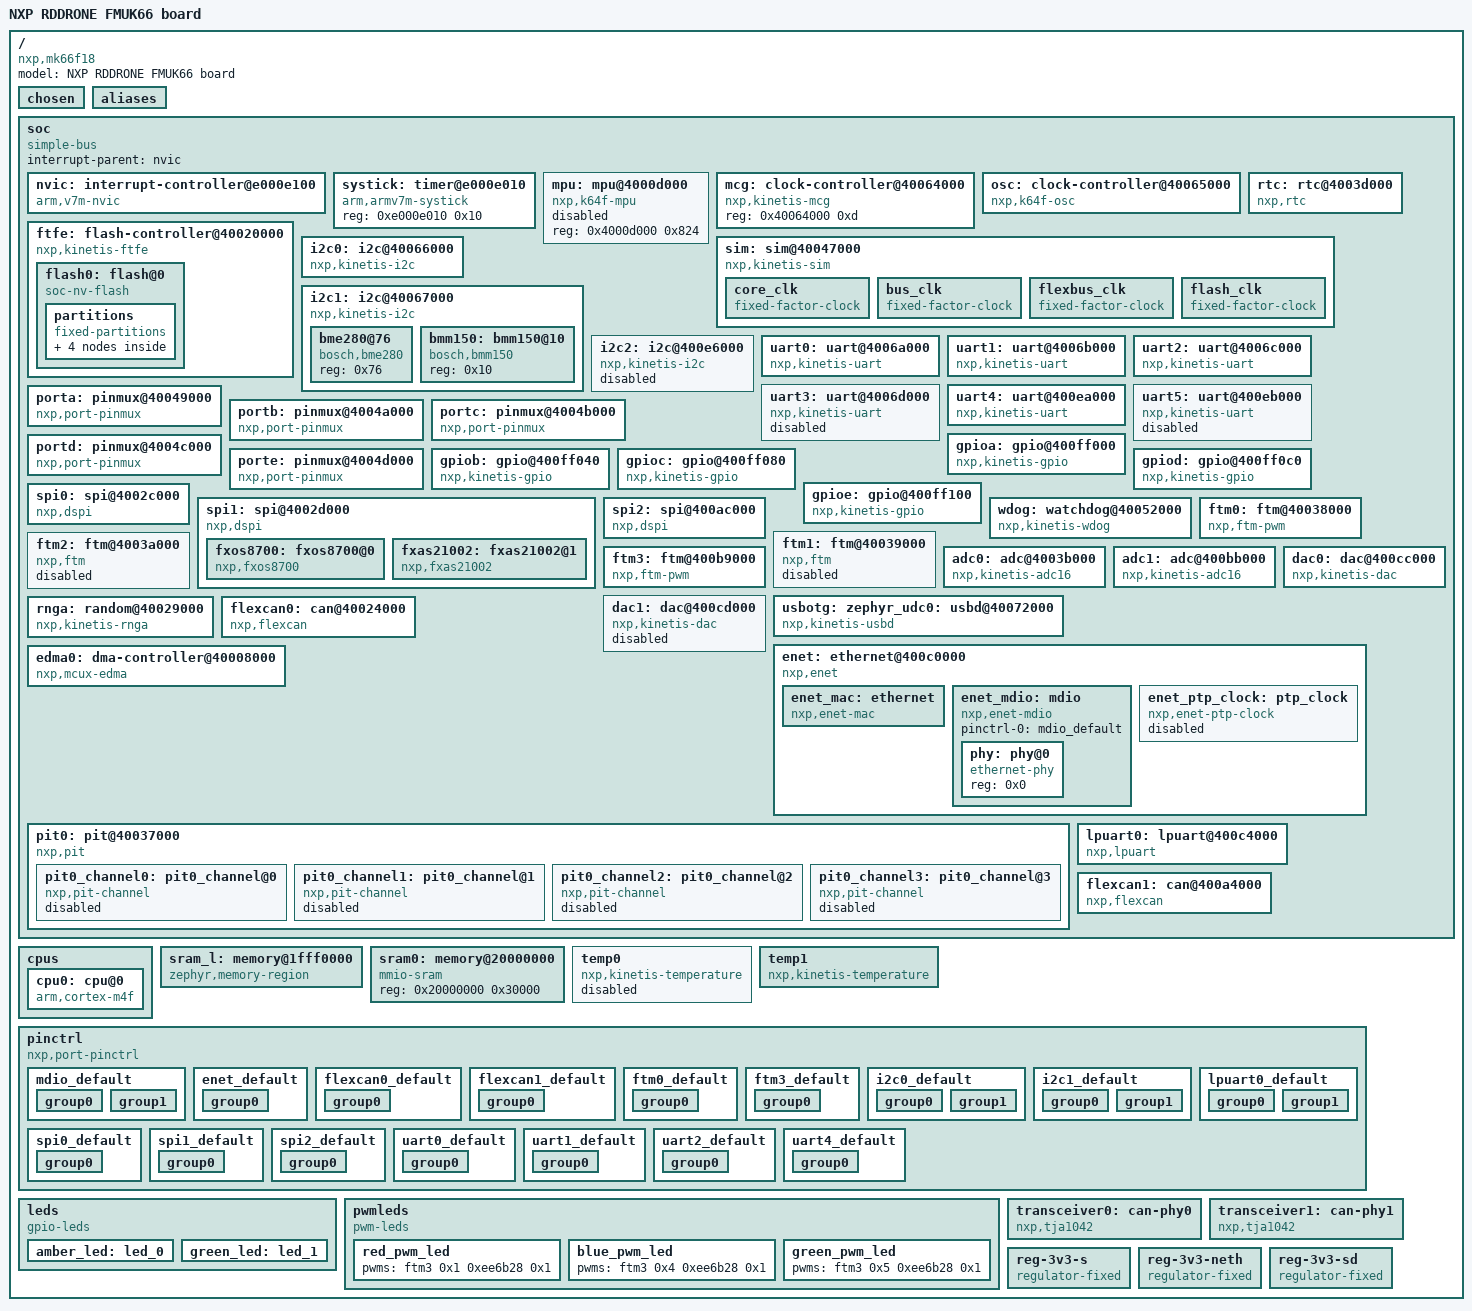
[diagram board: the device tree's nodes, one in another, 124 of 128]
/dts-v1/;

/* node '/' defined in zephyr/dts/common/skeleton.dtsi:9 */
/ {
	#address-cells = < 0x1 >;           /* in zephyr/dts/common/skeleton.dtsi:10 */
	#size-cells = < 0x1 >;              /* in zephyr/dts/common/skeleton.dtsi:11 */
	model = "NXP RDDRONE FMUK66 board"; /* in zephyr/boards/nxp/rddrone_fmuk66/rddrone_fmuk66.dts:15 */
	compatible = "nxp,mk66f18",
	             "nxp,k66f",
	             "nxp,k6x";             /* in zephyr/boards/nxp/rddrone_fmuk66/rddrone_fmuk66.dts:16 */

	/* node '/chosen' defined in zephyr/dts/common/skeleton.dtsi:13 */
	chosen {
		zephyr,entropy = &rnga;                   /* in zephyr/dts/arm/nxp/nxp_k6x.dtsi:18 */
		zephyr,flash-controller = &ftfe;          /* in zephyr/dts/arm/nxp/nxp_k6x.dtsi:19 */
		zephyr,sram = &sram0;                     /* in zephyr/boards/nxp/rddrone_fmuk66/rddrone_fmuk66.dts:38 */
		zephyr,flash = &flash0;                   /* in zephyr/boards/nxp/rddrone_fmuk66/rddrone_fmuk66.dts:39 */
		zephyr,code-partition = &slot0_partition; /* in zephyr/boards/nxp/rddrone_fmuk66/rddrone_fmuk66.dts:40 */
		zephyr,uart-mcumgr = &lpuart0;            /* in zephyr/boards/nxp/rddrone_fmuk66/rddrone_fmuk66.dts:41 */
		zephyr,console = &lpuart0;                /* in zephyr/boards/nxp/rddrone_fmuk66/rddrone_fmuk66.dts:42 */
		zephyr,shell-uart = &lpuart0;             /* in zephyr/boards/nxp/rddrone_fmuk66/rddrone_fmuk66.dts:43 */
		zephyr,uart-pipe = &lpuart0;              /* in zephyr/boards/nxp/rddrone_fmuk66/rddrone_fmuk66.dts:44 */
		zephyr,canbus = &flexcan0;                /* in zephyr/boards/nxp/rddrone_fmuk66/rddrone_fmuk66.dts:45 */
	};

	/* node '/aliases' defined in zephyr/dts/common/skeleton.dtsi:15 */
	aliases {
		watchdog0 = &wdog;              /* in zephyr/dts/arm/nxp/nxp_k6x.dtsi:14 */
		led0 = &amber_led;              /* in zephyr/boards/nxp/rddrone_fmuk66/rddrone_fmuk66.dts:19 */
		led1 = &green_led;              /* in zephyr/boards/nxp/rddrone_fmuk66/rddrone_fmuk66.dts:20 */
		pwm-led0 = &red_pwm_led;        /* in zephyr/boards/nxp/rddrone_fmuk66/rddrone_fmuk66.dts:21 */
		pwm-led1 = &green_pwm_led;      /* in zephyr/boards/nxp/rddrone_fmuk66/rddrone_fmuk66.dts:22 */
		pwm-led2 = &blue_pwm_led;       /* in zephyr/boards/nxp/rddrone_fmuk66/rddrone_fmuk66.dts:23 */
		magn0 = &bmm150;                /* in zephyr/boards/nxp/rddrone_fmuk66/rddrone_fmuk66.dts:24 */
		red-pwm-led = &red_pwm_led;     /* in zephyr/boards/nxp/rddrone_fmuk66/rddrone_fmuk66.dts:25 */
		green-pwm-led = &green_pwm_led; /* in zephyr/boards/nxp/rddrone_fmuk66/rddrone_fmuk66.dts:26 */
		blue-pwm-led = &blue_pwm_led;   /* in zephyr/boards/nxp/rddrone_fmuk66/rddrone_fmuk66.dts:27 */
		accel0 = &fxos8700;             /* in zephyr/boards/nxp/rddrone_fmuk66/rddrone_fmuk66.dts:28 */
	};

	/* node '/soc' defined in zephyr/dts/arm/armv7-m.dtsi:6 */
	soc {
		#address-cells = < 0x1 >;     /* in zephyr/dts/arm/armv7-m.dtsi:7 */
		#size-cells = < 0x1 >;        /* in zephyr/dts/arm/armv7-m.dtsi:8 */
		compatible = "simple-bus";    /* in zephyr/dts/arm/armv7-m.dtsi:9 */
		interrupt-parent = < &nvic >; /* in zephyr/dts/arm/armv7-m.dtsi:10 */
		ranges;                       /* in zephyr/dts/arm/armv7-m.dtsi:11 */

		/* node '/soc/interrupt-controller@e000e100' defined in zephyr/dts/arm/armv7-m.dtsi:13 */
		nvic: interrupt-controller@e000e100 {
			#address-cells = < 0x1 >;            /* in zephyr/dts/arm/armv7-m.dtsi:14 */
			compatible = "arm,v7m-nvic";         /* in zephyr/dts/arm/armv7-m.dtsi:15 */
			reg = < 0xe000e100 0xc00 >;          /* in zephyr/dts/arm/armv7-m.dtsi:16 */
			interrupt-controller;                /* in zephyr/dts/arm/armv7-m.dtsi:17 */
			#interrupt-cells = < 0x2 >;          /* in zephyr/dts/arm/armv7-m.dtsi:18 */
			arm,num-irq-priority-bits = < 0x4 >; /* in zephyr/dts/arm/nxp/nxp_k6x.dtsi:584 */
			phandle = < 0x1 >;                   /* in zephyr/dts/arm/armv7-m.dtsi:10 */
		};

		/* node '/soc/timer@e000e010' defined in zephyr/dts/arm/armv7-m.dtsi:21 */
		systick: timer@e000e010 {
			compatible = "arm,armv7m-systick"; /* in zephyr/dts/arm/armv7-m.dtsi:22 */
			reg = < 0xe000e010 0x10 >;         /* in zephyr/dts/arm/armv7-m.dtsi:23 */
		};

		/* node '/soc/mpu@4000d000' defined in zephyr/dts/arm/nxp/nxp_k6x.dtsi:82 */
		mpu: mpu@4000d000 {
			compatible = "nxp,k64f-mpu"; /* in zephyr/dts/arm/nxp/nxp_k6x.dtsi:83 */
			reg = < 0x4000d000 0x824 >;  /* in zephyr/dts/arm/nxp/nxp_k6x.dtsi:84 */
			status = "disabled";         /* in zephyr/dts/arm/nxp/nxp_k6x.dtsi:86 */
		};

		/* node '/soc/clock-controller@40064000' defined in zephyr/dts/arm/nxp/nxp_k6x.dtsi:89 */
		mcg: clock-controller@40064000 {
			compatible = "nxp,kinetis-mcg"; /* in zephyr/dts/arm/nxp/nxp_k6x.dtsi:90 */
			reg = < 0x40064000 0xd >;       /* in zephyr/dts/arm/nxp/nxp_k6x.dtsi:91 */
			#clock-cells = < 0x1 >;         /* in zephyr/dts/arm/nxp/nxp_k6x.dtsi:92 */
			phandle = < 0x2 >;              /* in zephyr/dts/arm/nxp/nxp_k6x.dtsi:118 */
		};

		/* node '/soc/clock-controller@40065000' defined in zephyr/dts/arm/nxp/nxp_k6x.dtsi:95 */
		osc: clock-controller@40065000 {
			compatible = "nxp,k64f-osc"; /* in zephyr/dts/arm/nxp/nxp_k6x.dtsi:96 */
			reg = < 0x40065000 0x4 >;    /* in zephyr/dts/arm/nxp/nxp_k6x.dtsi:97 */
			enable-external-reference;   /* in zephyr/dts/arm/nxp/nxp_k6x.dtsi:99 */
		};

		/* node '/soc/rtc@4003d000' defined in zephyr/dts/arm/nxp/nxp_k6x.dtsi:102 */
		rtc: rtc@4003d000 {
			compatible = "nxp,rtc";       /* in zephyr/dts/arm/nxp/nxp_k6x.dtsi:103 */
			reg = < 0x4003d000 0x1000 >;  /* in zephyr/dts/arm/nxp/nxp_k6x.dtsi:104 */
			interrupts = < 0x2e 0x0 >,
			             < 0x2f 0x0 >;    /* in zephyr/dts/arm/nxp/nxp_k6x.dtsi:105 */
			interrupt-names = "alarm",
			                  "seconds";  /* in zephyr/dts/arm/nxp/nxp_k6x.dtsi:106 */
			clock-frequency = < 0x8000 >; /* in zephyr/dts/arm/nxp/nxp_k6x.dtsi:107 */
			prescaler = < 0x8000 >;       /* in zephyr/dts/arm/nxp/nxp_k6x.dtsi:108 */
		};

		/* node '/soc/sim@40047000' defined in zephyr/dts/arm/nxp/nxp_k6x.dtsi:111 */
		sim: sim@40047000 {
			compatible = "nxp,kinetis-sim"; /* in zephyr/dts/arm/nxp/nxp_k6x.dtsi:112 */
			reg = < 0x40047000 0x1060 >;    /* in zephyr/dts/arm/nxp/nxp_k6x.dtsi:113 */
			#clock-cells = < 0x3 >;         /* in zephyr/dts/arm/nxp/nxp_k6x.dtsi:114 */
			pllfll-select = < 0x1 >;        /* in zephyr/boards/nxp/rddrone_fmuk66/rddrone_fmuk66.dts:122 */
			er32k-select = < 0x2 >;         /* in zephyr/boards/nxp/rddrone_fmuk66/rddrone_fmuk66.dts:123 */
			phandle = < 0x3 >;              /* in zephyr/dts/arm/nxp/nxp_k6x.dtsi:170 */

			/* node '/soc/sim@40047000/core_clk' defined in zephyr/dts/arm/nxp/nxp_k6x.dtsi:116 */
			core_clk {
				compatible = "fixed-factor-clock"; /* in zephyr/dts/arm/nxp/nxp_k6x.dtsi:117 */
				clocks = < &mcg 0x1 >;             /* in zephyr/dts/arm/nxp/nxp_k6x.dtsi:118 */
				clock-div = < 0x1 >;               /* in zephyr/dts/arm/nxp/nxp_k6x.dtsi:119 */
				#clock-cells = < 0x0 >;            /* in zephyr/dts/arm/nxp/nxp_k6x.dtsi:120 */
			};

			/* node '/soc/sim@40047000/bus_clk' defined in zephyr/dts/arm/nxp/nxp_k6x.dtsi:123 */
			bus_clk {
				compatible = "fixed-factor-clock"; /* in zephyr/dts/arm/nxp/nxp_k6x.dtsi:124 */
				clocks = < &mcg 0x1 >;             /* in zephyr/dts/arm/nxp/nxp_k6x.dtsi:125 */
				clock-div = < 0x2 >;               /* in zephyr/dts/arm/nxp/nxp_k6x.dtsi:126 */
				#clock-cells = < 0x0 >;            /* in zephyr/dts/arm/nxp/nxp_k6x.dtsi:127 */
			};

			/* node '/soc/sim@40047000/flexbus_clk' defined in zephyr/dts/arm/nxp/nxp_k6x.dtsi:130 */
			flexbus_clk {
				compatible = "fixed-factor-clock"; /* in zephyr/dts/arm/nxp/nxp_k6x.dtsi:131 */
				clocks = < &mcg 0x1 >;             /* in zephyr/dts/arm/nxp/nxp_k6x.dtsi:132 */
				clock-div = < 0x3 >;               /* in zephyr/dts/arm/nxp/nxp_k6x.dtsi:133 */
				#clock-cells = < 0x0 >;            /* in zephyr/dts/arm/nxp/nxp_k6x.dtsi:134 */
			};

			/* node '/soc/sim@40047000/flash_clk' defined in zephyr/dts/arm/nxp/nxp_k6x.dtsi:137 */
			flash_clk {
				compatible = "fixed-factor-clock"; /* in zephyr/dts/arm/nxp/nxp_k6x.dtsi:138 */
				clocks = < &mcg 0x1 >;             /* in zephyr/dts/arm/nxp/nxp_k6x.dtsi:139 */
				clock-div = < 0x5 >;               /* in zephyr/dts/arm/nxp/nxp_k6x.dtsi:140 */
				#clock-cells = < 0x0 >;            /* in zephyr/dts/arm/nxp/nxp_k6x.dtsi:141 */
			};
		};

		/* node '/soc/flash-controller@40020000' defined in zephyr/dts/arm/nxp/nxp_k6x.dtsi:145 */
		ftfe: flash-controller@40020000 {
			compatible = "nxp,kinetis-ftfe";      /* in zephyr/dts/arm/nxp/nxp_k6x.dtsi:146 */
			reg = < 0x40020000 0x18 >;            /* in zephyr/dts/arm/nxp/nxp_k6x.dtsi:147 */
			interrupts = < 0x12 0x0 >,
			             < 0x13 0x0 >;            /* in zephyr/dts/arm/nxp/nxp_k6x.dtsi:148 */
			interrupt-names = "command-complete",
			                  "read-collision";   /* in zephyr/dts/arm/nxp/nxp_k6x.dtsi:149 */
			status = "okay";                      /* in zephyr/dts/arm/nxp/nxp_k6x.dtsi:150 */
			#address-cells = < 0x1 >;             /* in zephyr/dts/arm/nxp/nxp_k6x.dtsi:152 */
			#size-cells = < 0x1 >;                /* in zephyr/dts/arm/nxp/nxp_k6x.dtsi:153 */

			/* node '/soc/flash-controller@40020000/flash@0' defined in zephyr/dts/arm/nxp/nxp_k6x.dtsi:155 */
			flash0: flash@0 {
				compatible = "soc-nv-flash";   /* in zephyr/dts/arm/nxp/nxp_k6x.dtsi:156 */
				erase-block-size = < 0x1000 >; /* in zephyr/dts/arm/nxp/nxp_k6x.dtsi:158 */
				write-block-size = < 0x8 >;    /* in zephyr/dts/arm/nxp/nxp_k6x.dtsi:159 */
				reg = < 0x0 0x200000 >;        /* in zephyr/dts/arm/nxp/nxp_k66.dtsi:12 */

				/* node '/soc/flash-controller@40020000/flash@0/partitions' defined in zephyr/boards/nxp/rddrone_fmuk66/rddrone_fmuk66.dts:236 */
				partitions {
					compatible = "fixed-partitions"; /* in zephyr/boards/nxp/rddrone_fmuk66/rddrone_fmuk66.dts:237 */
					#address-cells = < 0x1 >;        /* in zephyr/boards/nxp/rddrone_fmuk66/rddrone_fmuk66.dts:238 */
					#size-cells = < 0x1 >;           /* in zephyr/boards/nxp/rddrone_fmuk66/rddrone_fmuk66.dts:239 */

					/* node '/soc/flash-controller@40020000/flash@0/partitions/partition@0' defined in zephyr/boards/nxp/rddrone_fmuk66/rddrone_fmuk66.dts:245 */
					boot_partition: partition@0 {
						label = "mcuboot";     /* in zephyr/boards/nxp/rddrone_fmuk66/rddrone_fmuk66.dts:246 */
						reg = < 0x0 0x10000 >; /* in zephyr/boards/nxp/rddrone_fmuk66/rddrone_fmuk66.dts:247 */
						read-only;             /* in zephyr/boards/nxp/rddrone_fmuk66/rddrone_fmuk66.dts:248 */
					};

					/* node '/soc/flash-controller@40020000/flash@0/partitions/partition@10000' defined in zephyr/boards/nxp/rddrone_fmuk66/rddrone_fmuk66.dts:251 */
					slot0_partition: partition@10000 {
						label = "image-0";         /* in zephyr/boards/nxp/rddrone_fmuk66/rddrone_fmuk66.dts:252 */
						reg = < 0x10000 0xe9000 >; /* in zephyr/boards/nxp/rddrone_fmuk66/rddrone_fmuk66.dts:253 */
					};

					/* node '/soc/flash-controller@40020000/flash@0/partitions/partition@F9000' defined in zephyr/boards/nxp/rddrone_fmuk66/rddrone_fmuk66.dts:256 */
					slot1_partition: partition@F9000 {
						label = "image-1";         /* in zephyr/boards/nxp/rddrone_fmuk66/rddrone_fmuk66.dts:257 */
						reg = < 0xf9000 0xe9000 >; /* in zephyr/boards/nxp/rddrone_fmuk66/rddrone_fmuk66.dts:258 */
					};

					/* node '/soc/flash-controller@40020000/flash@0/partitions/partition@1E2000' defined in zephyr/boards/nxp/rddrone_fmuk66/rddrone_fmuk66.dts:261 */
					storage_partition: partition@1E2000 {
						label = "storage";          /* in zephyr/boards/nxp/rddrone_fmuk66/rddrone_fmuk66.dts:262 */
						reg = < 0x1e2000 0x1e000 >; /* in zephyr/boards/nxp/rddrone_fmuk66/rddrone_fmuk66.dts:263 */
					};
				};
			};
		};

		/* node '/soc/i2c@40066000' defined in zephyr/dts/arm/nxp/nxp_k6x.dtsi:163 */
		i2c0: i2c@40066000 {
			compatible = "nxp,kinetis-i2c";   /* in zephyr/dts/arm/nxp/nxp_k6x.dtsi:164 */
			clock-frequency = < 0x186a0 >;    /* in zephyr/dts/arm/nxp/nxp_k6x.dtsi:165 */
			#address-cells = < 0x1 >;         /* in zephyr/dts/arm/nxp/nxp_k6x.dtsi:166 */
			#size-cells = < 0x0 >;            /* in zephyr/dts/arm/nxp/nxp_k6x.dtsi:167 */
			reg = < 0x40066000 0x1000 >;      /* in zephyr/dts/arm/nxp/nxp_k6x.dtsi:168 */
			interrupts = < 0x18 0x0 >;        /* in zephyr/dts/arm/nxp/nxp_k6x.dtsi:169 */
			clocks = < &sim 0x2 0x1034 0x6 >; /* in zephyr/dts/arm/nxp/nxp_k6x.dtsi:170 */
			status = "okay";                  /* in zephyr/boards/nxp/rddrone_fmuk66/rddrone_fmuk66.dts:305 */
			pinctrl-0 = < &i2c0_default >;    /* in zephyr/boards/nxp/rddrone_fmuk66/rddrone_fmuk66.dts:306 */
			pinctrl-names = "default";        /* in zephyr/boards/nxp/rddrone_fmuk66/rddrone_fmuk66.dts:307 */
		};

		/* node '/soc/i2c@40067000' defined in zephyr/dts/arm/nxp/nxp_k6x.dtsi:174 */
		i2c1: i2c@40067000 {
			compatible = "nxp,kinetis-i2c";   /* in zephyr/dts/arm/nxp/nxp_k6x.dtsi:175 */
			clock-frequency = < 0x186a0 >;    /* in zephyr/dts/arm/nxp/nxp_k6x.dtsi:176 */
			#address-cells = < 0x1 >;         /* in zephyr/dts/arm/nxp/nxp_k6x.dtsi:177 */
			#size-cells = < 0x0 >;            /* in zephyr/dts/arm/nxp/nxp_k6x.dtsi:178 */
			reg = < 0x40067000 0x1000 >;      /* in zephyr/dts/arm/nxp/nxp_k6x.dtsi:179 */
			interrupts = < 0x19 0x0 >;        /* in zephyr/dts/arm/nxp/nxp_k6x.dtsi:180 */
			clocks = < &sim 0x2 0x1034 0x7 >; /* in zephyr/dts/arm/nxp/nxp_k6x.dtsi:181 */
			status = "okay";                  /* in zephyr/boards/nxp/rddrone_fmuk66/rddrone_fmuk66.dts:314 */
			pinctrl-0 = < &i2c1_default >;    /* in zephyr/boards/nxp/rddrone_fmuk66/rddrone_fmuk66.dts:315 */
			pinctrl-names = "default";        /* in zephyr/boards/nxp/rddrone_fmuk66/rddrone_fmuk66.dts:316 */

			/* node '/soc/i2c@40067000/bme280@76' defined in zephyr/boards/nxp/rddrone_fmuk66/rddrone_fmuk66.dts:323 */
			bme280@76 {
				compatible = "bosch,bme280"; /* in zephyr/boards/nxp/rddrone_fmuk66/rddrone_fmuk66.dts:324 */
				status = "okay";             /* in zephyr/boards/nxp/rddrone_fmuk66/rddrone_fmuk66.dts:325 */
				reg = < 0x76 >;              /* in zephyr/boards/nxp/rddrone_fmuk66/rddrone_fmuk66.dts:326 */
			};

			/* node '/soc/i2c@40067000/bmm150@10' defined in zephyr/boards/nxp/rddrone_fmuk66/rddrone_fmuk66.dts:329 */
			bmm150: bmm150@10 {
				compatible = "bosch,bmm150"; /* in zephyr/boards/nxp/rddrone_fmuk66/rddrone_fmuk66.dts:330 */
				status = "okay";             /* in zephyr/boards/nxp/rddrone_fmuk66/rddrone_fmuk66.dts:331 */
				reg = < 0x10 >;              /* in zephyr/boards/nxp/rddrone_fmuk66/rddrone_fmuk66.dts:332 */
			};
		};

		/* node '/soc/i2c@400e6000' defined in zephyr/dts/arm/nxp/nxp_k6x.dtsi:185 */
		i2c2: i2c@400e6000 {
			compatible = "nxp,kinetis-i2c";   /* in zephyr/dts/arm/nxp/nxp_k6x.dtsi:186 */
			clock-frequency = < 0x186a0 >;    /* in zephyr/dts/arm/nxp/nxp_k6x.dtsi:187 */
			#address-cells = < 0x1 >;         /* in zephyr/dts/arm/nxp/nxp_k6x.dtsi:188 */
			#size-cells = < 0x0 >;            /* in zephyr/dts/arm/nxp/nxp_k6x.dtsi:189 */
			reg = < 0x400e6000 0x1000 >;      /* in zephyr/dts/arm/nxp/nxp_k6x.dtsi:190 */
			interrupts = < 0x4a 0x0 >;        /* in zephyr/dts/arm/nxp/nxp_k6x.dtsi:191 */
			clocks = < &sim 0x2 0x1028 0x6 >; /* in zephyr/dts/arm/nxp/nxp_k6x.dtsi:192 */
			status = "disabled";              /* in zephyr/dts/arm/nxp/nxp_k6x.dtsi:193 */
		};

		/* node '/soc/uart@4006a000' defined in zephyr/dts/arm/nxp/nxp_k6x.dtsi:196 */
		uart0: uart@4006a000 {
			compatible = "nxp,kinetis-uart";  /* in zephyr/dts/arm/nxp/nxp_k6x.dtsi:197 */
			reg = < 0x4006a000 0x1000 >;      /* in zephyr/dts/arm/nxp/nxp_k6x.dtsi:198 */
			interrupts = < 0x1f 0x0 >,
			             < 0x20 0x0 >;        /* in zephyr/dts/arm/nxp/nxp_k6x.dtsi:199 */
			interrupt-names = "status",
			                  "error";        /* in zephyr/dts/arm/nxp/nxp_k6x.dtsi:200 */
			clocks = < &sim 0x0 0x1034 0xa >; /* in zephyr/dts/arm/nxp/nxp_k6x.dtsi:201 */
			status = "okay";                  /* in zephyr/boards/nxp/rddrone_fmuk66/rddrone_fmuk66.dts:182 */
			current-speed = < 0x1c200 >;      /* in zephyr/boards/nxp/rddrone_fmuk66/rddrone_fmuk66.dts:183 */
			pinctrl-0 = < &uart0_default >;   /* in zephyr/boards/nxp/rddrone_fmuk66/rddrone_fmuk66.dts:184 */
			pinctrl-names = "default";        /* in zephyr/boards/nxp/rddrone_fmuk66/rddrone_fmuk66.dts:185 */
		};

		/* node '/soc/uart@4006b000' defined in zephyr/dts/arm/nxp/nxp_k6x.dtsi:206 */
		uart1: uart@4006b000 {
			compatible = "nxp,kinetis-uart";  /* in zephyr/dts/arm/nxp/nxp_k6x.dtsi:207 */
			reg = < 0x4006b000 0x1000 >;      /* in zephyr/dts/arm/nxp/nxp_k6x.dtsi:208 */
			interrupts = < 0x21 0x0 >,
			             < 0x22 0x0 >;        /* in zephyr/dts/arm/nxp/nxp_k6x.dtsi:209 */
			interrupt-names = "status",
			                  "error";        /* in zephyr/dts/arm/nxp/nxp_k6x.dtsi:210 */
			clocks = < &sim 0x0 0x1034 0xb >; /* in zephyr/dts/arm/nxp/nxp_k6x.dtsi:211 */
			status = "okay";                  /* in zephyr/boards/nxp/rddrone_fmuk66/rddrone_fmuk66.dts:189 */
			current-speed = < 0x1c200 >;      /* in zephyr/boards/nxp/rddrone_fmuk66/rddrone_fmuk66.dts:190 */
			pinctrl-0 = < &uart1_default >;   /* in zephyr/boards/nxp/rddrone_fmuk66/rddrone_fmuk66.dts:191 */
			pinctrl-names = "default";        /* in zephyr/boards/nxp/rddrone_fmuk66/rddrone_fmuk66.dts:192 */
		};

		/* node '/soc/uart@4006c000' defined in zephyr/dts/arm/nxp/nxp_k6x.dtsi:216 */
		uart2: uart@4006c000 {
			compatible = "nxp,kinetis-uart";  /* in zephyr/dts/arm/nxp/nxp_k6x.dtsi:217 */
			reg = < 0x4006c000 0x1000 >;      /* in zephyr/dts/arm/nxp/nxp_k6x.dtsi:218 */
			interrupts = < 0x23 0x0 >,
			             < 0x24 0x0 >;        /* in zephyr/dts/arm/nxp/nxp_k6x.dtsi:219 */
			interrupt-names = "status",
			                  "error";        /* in zephyr/dts/arm/nxp/nxp_k6x.dtsi:220 */
			clocks = < &sim 0x2 0x1034 0xc >; /* in zephyr/dts/arm/nxp/nxp_k6x.dtsi:221 */
			status = "okay";                  /* in zephyr/boards/nxp/rddrone_fmuk66/rddrone_fmuk66.dts:196 */
			current-speed = < 0x1c200 >;      /* in zephyr/boards/nxp/rddrone_fmuk66/rddrone_fmuk66.dts:197 */
			pinctrl-0 = < &uart2_default >;   /* in zephyr/boards/nxp/rddrone_fmuk66/rddrone_fmuk66.dts:198 */
			pinctrl-names = "default";        /* in zephyr/boards/nxp/rddrone_fmuk66/rddrone_fmuk66.dts:199 */
		};

		/* node '/soc/uart@4006d000' defined in zephyr/dts/arm/nxp/nxp_k6x.dtsi:226 */
		uart3: uart@4006d000 {
			compatible = "nxp,kinetis-uart";  /* in zephyr/dts/arm/nxp/nxp_k6x.dtsi:227 */
			reg = < 0x4006d000 0x1000 >;      /* in zephyr/dts/arm/nxp/nxp_k6x.dtsi:228 */
			interrupts = < 0x25 0x0 >,
			             < 0x26 0x0 >;        /* in zephyr/dts/arm/nxp/nxp_k6x.dtsi:229 */
			interrupt-names = "status",
			                  "error";        /* in zephyr/dts/arm/nxp/nxp_k6x.dtsi:230 */
			clocks = < &sim 0x2 0x1034 0xd >; /* in zephyr/dts/arm/nxp/nxp_k6x.dtsi:231 */
			status = "disabled";              /* in zephyr/dts/arm/nxp/nxp_k6x.dtsi:233 */
		};

		/* node '/soc/uart@400ea000' defined in zephyr/dts/arm/nxp/nxp_k6x.dtsi:236 */
		uart4: uart@400ea000 {
			compatible = "nxp,kinetis-uart";  /* in zephyr/dts/arm/nxp/nxp_k6x.dtsi:237 */
			reg = < 0x400ea000 0x1000 >;      /* in zephyr/dts/arm/nxp/nxp_k6x.dtsi:238 */
			interrupts = < 0x42 0x0 >,
			             < 0x43 0x0 >;        /* in zephyr/dts/arm/nxp/nxp_k6x.dtsi:239 */
			interrupt-names = "status",
			                  "error";        /* in zephyr/dts/arm/nxp/nxp_k6x.dtsi:240 */
			clocks = < &sim 0x2 0x1028 0xa >; /* in zephyr/dts/arm/nxp/nxp_k6x.dtsi:241 */
			status = "okay";                  /* in zephyr/boards/nxp/rddrone_fmuk66/rddrone_fmuk66.dts:203 */
			current-speed = < 0x1c200 >;      /* in zephyr/boards/nxp/rddrone_fmuk66/rddrone_fmuk66.dts:204 */
			pinctrl-0 = < &uart4_default >;   /* in zephyr/boards/nxp/rddrone_fmuk66/rddrone_fmuk66.dts:205 */
			pinctrl-names = "default";        /* in zephyr/boards/nxp/rddrone_fmuk66/rddrone_fmuk66.dts:206 */
		};

		/* node '/soc/uart@400eb000' defined in zephyr/dts/arm/nxp/nxp_k6x.dtsi:246 */
		uart5: uart@400eb000 {
			compatible = "nxp,kinetis-uart";  /* in zephyr/dts/arm/nxp/nxp_k6x.dtsi:247 */
			reg = < 0x400eb000 0x1000 >;      /* in zephyr/dts/arm/nxp/nxp_k6x.dtsi:248 */
			interrupts = < 0x44 0x0 >,
			             < 0x45 0x0 >;        /* in zephyr/dts/arm/nxp/nxp_k6x.dtsi:249 */
			interrupt-names = "status",
			                  "error";        /* in zephyr/dts/arm/nxp/nxp_k6x.dtsi:250 */
			clocks = < &sim 0x2 0x1028 0xb >; /* in zephyr/dts/arm/nxp/nxp_k6x.dtsi:251 */
			status = "disabled";              /* in zephyr/dts/arm/nxp/nxp_k6x.dtsi:253 */
		};

		/* node '/soc/pinmux@40049000' defined in zephyr/dts/arm/nxp/nxp_k6x.dtsi:256 */
		porta: pinmux@40049000 {
			compatible = "nxp,port-pinmux";   /* in zephyr/dts/arm/nxp/nxp_k6x.dtsi:257 */
			reg = < 0x40049000 0xd0 >;        /* in zephyr/dts/arm/nxp/nxp_k6x.dtsi:258 */
			clocks = < &sim 0x2 0x1038 0x9 >; /* in zephyr/dts/arm/nxp/nxp_k6x.dtsi:259 */
			phandle = < 0xa >;                /* in zephyr/dts/arm/nxp/nxp_k6x.dtsi:293 */
		};

		/* node '/soc/pinmux@4004a000' defined in zephyr/dts/arm/nxp/nxp_k6x.dtsi:262 */
		portb: pinmux@4004a000 {
			compatible = "nxp,port-pinmux";   /* in zephyr/dts/arm/nxp/nxp_k6x.dtsi:263 */
			reg = < 0x4004a000 0xd0 >;        /* in zephyr/dts/arm/nxp/nxp_k6x.dtsi:264 */
			clocks = < &sim 0x2 0x1038 0xa >; /* in zephyr/dts/arm/nxp/nxp_k6x.dtsi:265 */
			phandle = < 0xb >;                /* in zephyr/dts/arm/nxp/nxp_k6x.dtsi:303 */
		};

		/* node '/soc/pinmux@4004b000' defined in zephyr/dts/arm/nxp/nxp_k6x.dtsi:268 */
		portc: pinmux@4004b000 {
			compatible = "nxp,port-pinmux";   /* in zephyr/dts/arm/nxp/nxp_k6x.dtsi:269 */
			reg = < 0x4004b000 0xd0 >;        /* in zephyr/dts/arm/nxp/nxp_k6x.dtsi:270 */
			clocks = < &sim 0x2 0x1038 0xb >; /* in zephyr/dts/arm/nxp/nxp_k6x.dtsi:271 */
			phandle = < 0xc >;                /* in zephyr/dts/arm/nxp/nxp_k6x.dtsi:313 */
		};

		/* node '/soc/pinmux@4004c000' defined in zephyr/dts/arm/nxp/nxp_k6x.dtsi:274 */
		portd: pinmux@4004c000 {
			compatible = "nxp,port-pinmux";   /* in zephyr/dts/arm/nxp/nxp_k6x.dtsi:275 */
			reg = < 0x4004c000 0xd0 >;        /* in zephyr/dts/arm/nxp/nxp_k6x.dtsi:276 */
			clocks = < &sim 0x2 0x1038 0xc >; /* in zephyr/dts/arm/nxp/nxp_k6x.dtsi:277 */
			phandle = < 0xd >;                /* in zephyr/dts/arm/nxp/nxp_k6x.dtsi:323 */
		};

		/* node '/soc/pinmux@4004d000' defined in zephyr/dts/arm/nxp/nxp_k6x.dtsi:280 */
		porte: pinmux@4004d000 {
			compatible = "nxp,port-pinmux";   /* in zephyr/dts/arm/nxp/nxp_k6x.dtsi:281 */
			reg = < 0x4004d000 0xd0 >;        /* in zephyr/dts/arm/nxp/nxp_k6x.dtsi:282 */
			clocks = < &sim 0x2 0x1038 0xd >; /* in zephyr/dts/arm/nxp/nxp_k6x.dtsi:283 */
			phandle = < 0xe >;                /* in zephyr/dts/arm/nxp/nxp_k6x.dtsi:333 */
		};

		/* node '/soc/gpio@400ff000' defined in zephyr/dts/arm/nxp/nxp_k6x.dtsi:286 */
		gpioa: gpio@400ff000 {
			compatible = "nxp,kinetis-gpio"; /* in zephyr/dts/arm/nxp/nxp_k6x.dtsi:287 */
			reg = < 0x400ff000 0x40 >;       /* in zephyr/dts/arm/nxp/nxp_k6x.dtsi:289 */
			interrupts = < 0x3b 0x2 >;       /* in zephyr/dts/arm/nxp/nxp_k6x.dtsi:290 */
			gpio-controller;                 /* in zephyr/dts/arm/nxp/nxp_k6x.dtsi:291 */
			#gpio-cells = < 0x2 >;           /* in zephyr/dts/arm/nxp/nxp_k6x.dtsi:292 */
			nxp,kinetis-port = < &porta >;   /* in zephyr/dts/arm/nxp/nxp_k6x.dtsi:293 */
			status = "okay";                 /* in zephyr/boards/nxp/rddrone_fmuk66/rddrone_fmuk66.dts:216 */
			phandle = < 0x13 >;              /* in zephyr/boards/nxp/rddrone_fmuk66/rddrone_fmuk66.dts:361 */
		};

		/* node '/soc/gpio@400ff040' defined in zephyr/dts/arm/nxp/nxp_k6x.dtsi:296 */
		gpiob: gpio@400ff040 {
			compatible = "nxp,kinetis-gpio"; /* in zephyr/dts/arm/nxp/nxp_k6x.dtsi:297 */
			reg = < 0x400ff040 0x40 >;       /* in zephyr/dts/arm/nxp/nxp_k6x.dtsi:299 */
			interrupts = < 0x3c 0x2 >;       /* in zephyr/dts/arm/nxp/nxp_k6x.dtsi:300 */
			gpio-controller;                 /* in zephyr/dts/arm/nxp/nxp_k6x.dtsi:301 */
			#gpio-cells = < 0x2 >;           /* in zephyr/dts/arm/nxp/nxp_k6x.dtsi:302 */
			nxp,kinetis-port = < &portb >;   /* in zephyr/dts/arm/nxp/nxp_k6x.dtsi:303 */
			status = "okay";                 /* in zephyr/boards/nxp/rddrone_fmuk66/rddrone_fmuk66.dts:220 */
			phandle = < 0x12 >;              /* in zephyr/boards/nxp/rddrone_fmuk66/rddrone_fmuk66.dts:353 */
		};

		/* node '/soc/gpio@400ff080' defined in zephyr/dts/arm/nxp/nxp_k6x.dtsi:306 */
		gpioc: gpio@400ff080 {
			compatible = "nxp,kinetis-gpio"; /* in zephyr/dts/arm/nxp/nxp_k6x.dtsi:307 */
			reg = < 0x400ff080 0x40 >;       /* in zephyr/dts/arm/nxp/nxp_k6x.dtsi:309 */
			interrupts = < 0x3d 0x2 >;       /* in zephyr/dts/arm/nxp/nxp_k6x.dtsi:310 */
			gpio-controller;                 /* in zephyr/dts/arm/nxp/nxp_k6x.dtsi:311 */
			#gpio-cells = < 0x2 >;           /* in zephyr/dts/arm/nxp/nxp_k6x.dtsi:312 */
			nxp,kinetis-port = < &portc >;   /* in zephyr/dts/arm/nxp/nxp_k6x.dtsi:313 */
			status = "okay";                 /* in zephyr/boards/nxp/rddrone_fmuk66/rddrone_fmuk66.dts:224 */
			phandle = < 0x26 >;              /* in zephyr/boards/nxp/rddrone_fmuk66/rddrone_fmuk66.dts:81 */
		};

		/* node '/soc/gpio@400ff0c0' defined in zephyr/dts/arm/nxp/nxp_k6x.dtsi:316 */
		gpiod: gpio@400ff0c0 {
			compatible = "nxp,kinetis-gpio"; /* in zephyr/dts/arm/nxp/nxp_k6x.dtsi:317 */
			reg = < 0x400ff0c0 0x40 >;       /* in zephyr/dts/arm/nxp/nxp_k6x.dtsi:319 */
			interrupts = < 0x3e 0x2 >;       /* in zephyr/dts/arm/nxp/nxp_k6x.dtsi:320 */
			gpio-controller;                 /* in zephyr/dts/arm/nxp/nxp_k6x.dtsi:321 */
			#gpio-cells = < 0x2 >;           /* in zephyr/dts/arm/nxp/nxp_k6x.dtsi:322 */
			nxp,kinetis-port = < &portd >;   /* in zephyr/dts/arm/nxp/nxp_k6x.dtsi:323 */
			status = "okay";                 /* in zephyr/boards/nxp/rddrone_fmuk66/rddrone_fmuk66.dts:228 */
			phandle = < 0x15 >;              /* in zephyr/boards/nxp/rddrone_fmuk66/rddrone_fmuk66.dts:371 */
		};

		/* node '/soc/gpio@400ff100' defined in zephyr/dts/arm/nxp/nxp_k6x.dtsi:326 */
		gpioe: gpio@400ff100 {
			compatible = "nxp,kinetis-gpio"; /* in zephyr/dts/arm/nxp/nxp_k6x.dtsi:327 */
			reg = < 0x400ff100 0x40 >;       /* in zephyr/dts/arm/nxp/nxp_k6x.dtsi:329 */
			interrupts = < 0x3f 0x2 >;       /* in zephyr/dts/arm/nxp/nxp_k6x.dtsi:330 */
			gpio-controller;                 /* in zephyr/dts/arm/nxp/nxp_k6x.dtsi:331 */
			#gpio-cells = < 0x2 >;           /* in zephyr/dts/arm/nxp/nxp_k6x.dtsi:332 */
			nxp,kinetis-port = < &porte >;   /* in zephyr/dts/arm/nxp/nxp_k6x.dtsi:333 */
			status = "okay";                 /* in zephyr/boards/nxp/rddrone_fmuk66/rddrone_fmuk66.dts:232 */
			phandle = < 0x14 >;              /* in zephyr/boards/nxp/rddrone_fmuk66/rddrone_fmuk66.dts:362 */
		};

		/* node '/soc/spi@4002c000' defined in zephyr/dts/arm/nxp/nxp_k6x.dtsi:336 */
		spi0: spi@4002c000 {
			compatible = "nxp,dspi";          /* in zephyr/dts/arm/nxp/nxp_k6x.dtsi:337 */
			reg = < 0x4002c000 0x88 >;        /* in zephyr/dts/arm/nxp/nxp_k6x.dtsi:338 */
			interrupts = < 0x1a 0x3 >;        /* in zephyr/dts/arm/nxp/nxp_k6x.dtsi:339 */
			dmas = < &edma0 0x0 0xe >,
			       < &edma0 0x0 0xf >;        /* in zephyr/dts/arm/nxp/nxp_k6x.dtsi:340 */
			dma-names = "rx",
			            "tx";                 /* in zephyr/dts/arm/nxp/nxp_k6x.dtsi:341 */
			rx-fifo-size = < 0x4 >;           /* in zephyr/dts/arm/nxp/nxp_k6x.dtsi:342 */
			tx-fifo-size = < 0x4 >;           /* in zephyr/dts/arm/nxp/nxp_k6x.dtsi:343 */
			clocks = < &sim 0x2 0x103c 0xc >; /* in zephyr/dts/arm/nxp/nxp_k6x.dtsi:344 */
			#address-cells = < 0x1 >;         /* in zephyr/dts/arm/nxp/nxp_k6x.dtsi:345 */
			#size-cells = < 0x0 >;            /* in zephyr/dts/arm/nxp/nxp_k6x.dtsi:346 */
			status = "okay";                  /* in zephyr/boards/nxp/rddrone_fmuk66/rddrone_fmuk66.dts:338 */
			pinctrl-0 = < &spi0_default >;    /* in zephyr/boards/nxp/rddrone_fmuk66/rddrone_fmuk66.dts:339 */
			pinctrl-names = "default";        /* in zephyr/boards/nxp/rddrone_fmuk66/rddrone_fmuk66.dts:340 */
		};

		/* node '/soc/spi@4002d000' defined in zephyr/dts/arm/nxp/nxp_k6x.dtsi:350 */
		spi1: spi@4002d000 {
			compatible = "nxp,dspi";          /* in zephyr/dts/arm/nxp/nxp_k6x.dtsi:351 */
			reg = < 0x4002d000 0x88 >;        /* in zephyr/dts/arm/nxp/nxp_k6x.dtsi:352 */
			interrupts = < 0x1b 0x3 >;        /* in zephyr/dts/arm/nxp/nxp_k6x.dtsi:353 */
			dmas = < &edma0 0x0 0x10 >,
			       < &edma0 0x0 0x10 >;       /* in zephyr/dts/arm/nxp/nxp_k6x.dtsi:354 */
			dma-names = "rx",
			            "tx";                 /* in zephyr/dts/arm/nxp/nxp_k6x.dtsi:355 */
			rx-fifo-size = < 0x1 >;           /* in zephyr/dts/arm/nxp/nxp_k6x.dtsi:356 */
			tx-fifo-size = < 0x1 >;           /* in zephyr/dts/arm/nxp/nxp_k6x.dtsi:357 */
			nxp,rx-tx-chn-share;              /* in zephyr/dts/arm/nxp/nxp_k6x.dtsi:358 */
			clocks = < &sim 0x2 0x103c 0xd >; /* in zephyr/dts/arm/nxp/nxp_k6x.dtsi:359 */
			#address-cells = < 0x1 >;         /* in zephyr/dts/arm/nxp/nxp_k6x.dtsi:360 */
			#size-cells = < 0x0 >;            /* in zephyr/dts/arm/nxp/nxp_k6x.dtsi:361 */
			status = "okay";                  /* in zephyr/boards/nxp/rddrone_fmuk66/rddrone_fmuk66.dts:345 */
			pinctrl-0 = < &spi1_default >;    /* in zephyr/boards/nxp/rddrone_fmuk66/rddrone_fmuk66.dts:346 */
			pinctrl-names = "default";        /* in zephyr/boards/nxp/rddrone_fmuk66/rddrone_fmuk66.dts:347 */
			cs-gpios = < &gpiob 0xa 0x1 >,
			           < &gpiob 0x9 0x1 >;    /* in zephyr/boards/nxp/rddrone_fmuk66/rddrone_fmuk66.dts:353 */
			clock-frequency = < 0xf4240 >;    /* in zephyr/boards/nxp/rddrone_fmuk66/rddrone_fmuk66.dts:355 */

			/* node '/soc/spi@4002d000/fxos8700@0' defined in zephyr/boards/nxp/rddrone_fmuk66/rddrone_fmuk66.dts:357 */
			fxos8700: fxos8700@0 {
				compatible = "nxp,fxos8700";       /* in zephyr/boards/nxp/rddrone_fmuk66/rddrone_fmuk66.dts:358 */
				reg = < 0x0 >;                     /* in zephyr/boards/nxp/rddrone_fmuk66/rddrone_fmuk66.dts:359 */
				spi-max-frequency = < 0xf4240 >;   /* in zephyr/boards/nxp/rddrone_fmuk66/rddrone_fmuk66.dts:360 */
				reset-gpios = < &gpioa 0x19 0x0 >; /* in zephyr/boards/nxp/rddrone_fmuk66/rddrone_fmuk66.dts:361 */
				int1-gpios = < &gpioe 0x9 0x1 >;   /* in zephyr/boards/nxp/rddrone_fmuk66/rddrone_fmuk66.dts:362 */
				int2-gpios = < &gpioe 0xa 0x1 >;   /* in zephyr/boards/nxp/rddrone_fmuk66/rddrone_fmuk66.dts:363 */
				status = "okay";                   /* in zephyr/boards/nxp/rddrone_fmuk66/rddrone_fmuk66.dts:364 */
			};

			/* node '/soc/spi@4002d000/fxas21002@1' defined in zephyr/boards/nxp/rddrone_fmuk66/rddrone_fmuk66.dts:367 */
			fxas21002: fxas21002@1 {
				compatible = "nxp,fxas21002";     /* in zephyr/boards/nxp/rddrone_fmuk66/rddrone_fmuk66.dts:368 */
				reg = < 0x1 >;                    /* in zephyr/boards/nxp/rddrone_fmuk66/rddrone_fmuk66.dts:369 */
				spi-max-frequency = < 0xf4240 >;  /* in zephyr/boards/nxp/rddrone_fmuk66/rddrone_fmuk66.dts:370 */
				reset-gpios = < &gpiod 0xc 0x1 >; /* in zephyr/boards/nxp/rddrone_fmuk66/rddrone_fmuk66.dts:371 */
				int1-gpios = < &gpioe 0x7 0x1 >;  /* in zephyr/boards/nxp/rddrone_fmuk66/rddrone_fmuk66.dts:372 */
				int2-gpios = < &gpioe 0x6 0x1 >;  /* in zephyr/boards/nxp/rddrone_fmuk66/rddrone_fmuk66.dts:373 */
				status = "okay";                  /* in zephyr/boards/nxp/rddrone_fmuk66/rddrone_fmuk66.dts:374 */
			};
		};

		/* node '/soc/spi@400ac000' defined in zephyr/dts/arm/nxp/nxp_k6x.dtsi:365 */
		spi2: spi@400ac000 {
			compatible = "nxp,dspi";          /* in zephyr/dts/arm/nxp/nxp_k6x.dtsi:366 */
			reg = < 0x400ac000 0x88 >;        /* in zephyr/dts/arm/nxp/nxp_k6x.dtsi:367 */
			interrupts = < 0x41 0x3 >;        /* in zephyr/dts/arm/nxp/nxp_k6x.dtsi:368 */
			dmas = < &edma0 0x0 0x26 >,
			       < &edma0 0x0 0x27 >;       /* in zephyr/dts/arm/nxp/nxp_k6x.dtsi:369 */
			dma-names = "rx",
			            "tx";                 /* in zephyr/dts/arm/nxp/nxp_k6x.dtsi:370 */
			rx-fifo-size = < 0x1 >;           /* in zephyr/dts/arm/nxp/nxp_k6x.dtsi:371 */
			tx-fifo-size = < 0x1 >;           /* in zephyr/dts/arm/nxp/nxp_k6x.dtsi:372 */
			nxp,rx-tx-chn-share;              /* in zephyr/dts/arm/nxp/nxp_k6x.dtsi:373 */
			clocks = < &sim 0x2 0x1030 0xc >; /* in zephyr/dts/arm/nxp/nxp_k6x.dtsi:374 */
			#address-cells = < 0x1 >;         /* in zephyr/dts/arm/nxp/nxp_k6x.dtsi:375 */
			#size-cells = < 0x0 >;            /* in zephyr/dts/arm/nxp/nxp_k6x.dtsi:376 */
			status = "okay";                  /* in zephyr/boards/nxp/rddrone_fmuk66/rddrone_fmuk66.dts:380 */
			pinctrl-0 = < &spi2_default >;    /* in zephyr/boards/nxp/rddrone_fmuk66/rddrone_fmuk66.dts:381 */
			pinctrl-names = "default";        /* in zephyr/boards/nxp/rddrone_fmuk66/rddrone_fmuk66.dts:382 */
		};

		/* node '/soc/watchdog@40052000' defined in zephyr/dts/arm/nxp/nxp_k6x.dtsi:380 */
		wdog: watchdog@40052000 {
			compatible = "nxp,kinetis-wdog"; /* in zephyr/dts/arm/nxp/nxp_k6x.dtsi:381 */
			reg = < 0x40052000 0x10 >;       /* in zephyr/dts/arm/nxp/nxp_k6x.dtsi:382 */
			interrupts = < 0x16 0x0 >;       /* in zephyr/dts/arm/nxp/nxp_k6x.dtsi:383 */
			clocks = < &sim 0x13 0x0 0x0 >;  /* in zephyr/dts/arm/nxp/nxp_k6x.dtsi:384 */
		};

		/* node '/soc/ftm@40038000' defined in zephyr/dts/arm/nxp/nxp_k6x.dtsi:387 */
		ftm0: ftm@40038000 {
			reg = < 0x40038000 0x98 >;     /* in zephyr/dts/arm/nxp/nxp_k6x.dtsi:389 */
			interrupts = < 0x2a 0x0 >;     /* in zephyr/dts/arm/nxp/nxp_k6x.dtsi:390 */
			clocks = < &mcg 0x0 >;         /* in zephyr/dts/arm/nxp/nxp_k6x.dtsi:391 */
			prescaler = < 0x10 >;          /* in zephyr/dts/arm/nxp/nxp_k6x.dtsi:392 */
			status = "okay";               /* in zephyr/boards/nxp/rddrone_fmuk66/rddrone_fmuk66.dts:149 */
			compatible = "nxp,ftm-pwm";    /* in zephyr/boards/nxp/rddrone_fmuk66/rddrone_fmuk66.dts:150 */
			#pwm-cells = < 0x3 >;          /* in zephyr/boards/nxp/rddrone_fmuk66/rddrone_fmuk66.dts:151 */
			pinctrl-0 = < &ftm0_default >; /* in zephyr/boards/nxp/rddrone_fmuk66/rddrone_fmuk66.dts:152 */
			pinctrl-names = "default";     /* in zephyr/boards/nxp/rddrone_fmuk66/rddrone_fmuk66.dts:153 */
			clock-source = "fixed";        /* in zephyr/boards/nxp/rddrone_fmuk66/rddrone_fmuk66.dts:154 */
		};

		/* node '/soc/ftm@40039000' defined in zephyr/dts/arm/nxp/nxp_k6x.dtsi:396 */
		ftm1: ftm@40039000 {
			compatible = "nxp,ftm";    /* in zephyr/dts/arm/nxp/nxp_k6x.dtsi:397 */
			reg = < 0x40039000 0x98 >; /* in zephyr/dts/arm/nxp/nxp_k6x.dtsi:398 */
			interrupts = < 0x2b 0x0 >; /* in zephyr/dts/arm/nxp/nxp_k6x.dtsi:399 */
			clocks = < &mcg 0x0 >;     /* in zephyr/dts/arm/nxp/nxp_k6x.dtsi:400 */
			prescaler = < 0x10 >;      /* in zephyr/dts/arm/nxp/nxp_k6x.dtsi:401 */
			status = "disabled";       /* in zephyr/dts/arm/nxp/nxp_k6x.dtsi:402 */
		};

		/* node '/soc/ftm@4003a000' defined in zephyr/dts/arm/nxp/nxp_k6x.dtsi:405 */
		ftm2: ftm@4003a000 {
			compatible = "nxp,ftm";    /* in zephyr/dts/arm/nxp/nxp_k6x.dtsi:406 */
			reg = < 0x4003a000 0x98 >; /* in zephyr/dts/arm/nxp/nxp_k6x.dtsi:407 */
			interrupts = < 0x2c 0x0 >; /* in zephyr/dts/arm/nxp/nxp_k6x.dtsi:408 */
			clocks = < &mcg 0x0 >;     /* in zephyr/dts/arm/nxp/nxp_k6x.dtsi:409 */
			prescaler = < 0x10 >;      /* in zephyr/dts/arm/nxp/nxp_k6x.dtsi:410 */
			status = "disabled";       /* in zephyr/dts/arm/nxp/nxp_k6x.dtsi:411 */
		};

		/* node '/soc/ftm@400b9000' defined in zephyr/dts/arm/nxp/nxp_k6x.dtsi:414 */
		ftm3: ftm@400b9000 {
			reg = < 0x400b9000 0x98 >;     /* in zephyr/dts/arm/nxp/nxp_k6x.dtsi:416 */
			interrupts = < 0x47 0x0 >;     /* in zephyr/dts/arm/nxp/nxp_k6x.dtsi:417 */
			clocks = < &mcg 0x0 >;         /* in zephyr/dts/arm/nxp/nxp_k6x.dtsi:418 */
			prescaler = < 0x10 >;          /* in zephyr/dts/arm/nxp/nxp_k6x.dtsi:419 */
			status = "okay";               /* in zephyr/boards/nxp/rddrone_fmuk66/rddrone_fmuk66.dts:159 */
			compatible = "nxp,ftm-pwm";    /* in zephyr/boards/nxp/rddrone_fmuk66/rddrone_fmuk66.dts:160 */
			#pwm-cells = < 0x3 >;          /* in zephyr/boards/nxp/rddrone_fmuk66/rddrone_fmuk66.dts:161 */
			pinctrl-0 = < &ftm3_default >; /* in zephyr/boards/nxp/rddrone_fmuk66/rddrone_fmuk66.dts:162 */
			pinctrl-names = "default";     /* in zephyr/boards/nxp/rddrone_fmuk66/rddrone_fmuk66.dts:163 */
			clock-source = "fixed";        /* in zephyr/boards/nxp/rddrone_fmuk66/rddrone_fmuk66.dts:164 */
			phandle = < 0x25 >;            /* in zephyr/boards/nxp/rddrone_fmuk66/rddrone_fmuk66.dts:66 */
		};

		/* node '/soc/adc@4003b000' defined in zephyr/dts/arm/nxp/nxp_k6x.dtsi:423 */
		adc0: adc@4003b000 {
			compatible = "nxp,kinetis-adc16"; /* in zephyr/dts/arm/nxp/nxp_k6x.dtsi:424 */
			reg = < 0x4003b000 0x70 >;        /* in zephyr/dts/arm/nxp/nxp_k6x.dtsi:425 */
			clocks = < &sim 0x7 0x0 0xf >,
			         < &sim 0x7 0x7 0x80 >;   /* in zephyr/dts/arm/nxp/nxp_k6x.dtsi:426 */
			dmas = < &edma0 0x0 0x28 >;       /* in zephyr/dts/arm/nxp/nxp_k6x.dtsi:428 */
			dma-names = "adc0";               /* in zephyr/dts/arm/nxp/nxp_k6x.dtsi:429 */
			clk-source = < 0x0 >;             /* in zephyr/dts/arm/nxp/nxp_k6x.dtsi:430 */
			interrupts = < 0x27 0x0 >;        /* in zephyr/dts/arm/nxp/nxp_k6x.dtsi:431 */
			#io-channel-cells = < 0x1 >;      /* in zephyr/dts/arm/nxp/nxp_k6x.dtsi:433 */
			status = "okay";                  /* in zephyr/boards/nxp/rddrone_fmuk66/rddrone_fmuk66.dts:131 */
			phandle = < 0x23 >;               /* in zephyr/dts/arm/nxp/nxp_k6x.dtsi:55 */
		};

		/* node '/soc/adc@400bb000' defined in zephyr/dts/arm/nxp/nxp_k6x.dtsi:436 */
		adc1: adc@400bb000 {
			compatible = "nxp,kinetis-adc16"; /* in zephyr/dts/arm/nxp/nxp_k6x.dtsi:437 */
			reg = < 0x400bb000 0x70 >;        /* in zephyr/dts/arm/nxp/nxp_k6x.dtsi:438 */
			clocks = < &sim 0x7 0x8 0xf00 >,
			         < &sim 0x7 0xf 0x8000 >; /* in zephyr/dts/arm/nxp/nxp_k6x.dtsi:439 */
			dmas = < &edma0 0x0 0x29 >;       /* in zephyr/dts/arm/nxp/nxp_k6x.dtsi:441 */
			dma-names = "adc1";               /* in zephyr/dts/arm/nxp/nxp_k6x.dtsi:442 */
			clk-source = < 0x0 >;             /* in zephyr/dts/arm/nxp/nxp_k6x.dtsi:443 */
			interrupts = < 0x49 0x0 >;        /* in zephyr/dts/arm/nxp/nxp_k6x.dtsi:444 */
			#io-channel-cells = < 0x1 >;      /* in zephyr/dts/arm/nxp/nxp_k6x.dtsi:446 */
			status = "okay";                  /* in zephyr/boards/nxp/rddrone_fmuk66/rddrone_fmuk66.dts:135 */
			phandle = < 0x24 >;               /* in zephyr/dts/arm/nxp/nxp_k6x.dtsi:66 */
		};

		/* node '/soc/dac@400cc000' defined in zephyr/dts/arm/nxp/nxp_k6x.dtsi:449 */
		dac0: dac@400cc000 {
			compatible = "nxp,kinetis-dac"; /* in zephyr/dts/arm/nxp/nxp_k6x.dtsi:450 */
			reg = < 0x400cc000 0x1000 >;    /* in zephyr/dts/arm/nxp/nxp_k6x.dtsi:451 */
			interrupts = < 0x38 0x0 >;      /* in zephyr/dts/arm/nxp/nxp_k6x.dtsi:452 */
			#io-channel-cells = < 0x1 >;    /* in zephyr/dts/arm/nxp/nxp_k6x.dtsi:455 */
			status = "okay";                /* in zephyr/boards/nxp/rddrone_fmuk66/rddrone_fmuk66.dts:143 */
			voltage-reference = < 0x2 >;    /* in zephyr/boards/nxp/rddrone_fmuk66/rddrone_fmuk66.dts:144 */
		};

		/* node '/soc/dac@400cd000' defined in zephyr/dts/arm/nxp/nxp_k6x.dtsi:458 */
		dac1: dac@400cd000 {
			compatible = "nxp,kinetis-dac"; /* in zephyr/dts/arm/nxp/nxp_k6x.dtsi:459 */
			reg = < 0x400cd000 0x1000 >;    /* in zephyr/dts/arm/nxp/nxp_k6x.dtsi:460 */
			interrupts = < 0x48 0x0 >;      /* in zephyr/dts/arm/nxp/nxp_k6x.dtsi:461 */
			voltage-reference = < 0x1 >;    /* in zephyr/dts/arm/nxp/nxp_k6x.dtsi:462 */
			status = "disabled";            /* in zephyr/dts/arm/nxp/nxp_k6x.dtsi:463 */
			#io-channel-cells = < 0x1 >;    /* in zephyr/dts/arm/nxp/nxp_k6x.dtsi:464 */
		};

		/* node '/soc/usbd@40072000' defined in zephyr/dts/arm/nxp/nxp_k6x.dtsi:467 */
		usbotg: zephyr_udc0: usbd@40072000 {
			reg = < 0x40072000 0x1000 >;     /* in zephyr/dts/arm/nxp/nxp_k6x.dtsi:469 */
			interrupts = < 0x35 0x1 >;       /* in zephyr/dts/arm/nxp/nxp_k6x.dtsi:470 */
			interrupt-names = "usb_otg";     /* in zephyr/dts/arm/nxp/nxp_k6x.dtsi:471 */
			compatible = "nxp,kinetis-usbd"; /* in zephyr/boards/nxp/rddrone_fmuk66/rddrone_fmuk66.dts:210 */
			status = "okay";                 /* in zephyr/boards/nxp/rddrone_fmuk66/rddrone_fmuk66.dts:211 */
			num-bidir-endpoints = < 0x8 >;   /* in zephyr/boards/nxp/rddrone_fmuk66/rddrone_fmuk66.dts:212 */
		};

		/* node '/soc/ethernet@400c0000' defined in zephyr/dts/arm/nxp/nxp_k6x.dtsi:476 */
		enet: ethernet@400c0000 {
			compatible = "nxp,enet";          /* in zephyr/dts/arm/nxp/nxp_k6x.dtsi:477 */
			reg = < 0x400c0000 0x620 >;       /* in zephyr/dts/arm/nxp/nxp_k6x.dtsi:478 */
			clocks = < &sim 0x10e1 0x0 0x0 >; /* in zephyr/dts/arm/nxp/nxp_k6x.dtsi:479 */

			/* node '/soc/ethernet@400c0000/ethernet' defined in zephyr/dts/arm/nxp/nxp_k6x.dtsi:481 */
			enet_mac: ethernet {
				compatible = "nxp,enet-mac";     /* in zephyr/dts/arm/nxp/nxp_k6x.dtsi:482 */
				interrupts = < 0x53 0x0 >,
				             < 0x54 0x0 >,
				             < 0x55 0x0 >;       /* in zephyr/dts/arm/nxp/nxp_k6x.dtsi:483 */
				interrupt-names = "TX",
				                  "RX",
				                  "ERR";         /* in zephyr/dts/arm/nxp/nxp_k6x.dtsi:484 */
				nxp,mdio = < &enet_mdio >;       /* in zephyr/dts/arm/nxp/nxp_k6x.dtsi:485 */
				ptp-clock = < &enet_ptp_clock >; /* in zephyr/dts/arm/nxp/nxp_k6x.dtsi:486 */
				status = "okay";                 /* in zephyr/boards/nxp/rddrone_fmuk66/rddrone_fmuk66.dts:269 */
				pinctrl-0 = < &enet_default >;   /* in zephyr/boards/nxp/rddrone_fmuk66/rddrone_fmuk66.dts:270 */
				pinctrl-names = "default";       /* in zephyr/boards/nxp/rddrone_fmuk66/rddrone_fmuk66.dts:271 */
				phy-connection-type = "rmii";    /* in zephyr/boards/nxp/rddrone_fmuk66/rddrone_fmuk66.dts:272 */
				phy-handle = < &phy >;           /* in zephyr/boards/nxp/rddrone_fmuk66/rddrone_fmuk66.dts:273 */
				zephyr,random-mac-address;       /* in zephyr/boards/nxp/rddrone_fmuk66/rddrone_fmuk66.dts:274 */
			};

			/* node '/soc/ethernet@400c0000/mdio' defined in zephyr/dts/arm/nxp/nxp_k6x.dtsi:491 */
			enet_mdio: mdio {
				compatible = "nxp,enet-mdio";  /* in zephyr/dts/arm/nxp/nxp_k6x.dtsi:492 */
				#address-cells = < 0x1 >;      /* in zephyr/dts/arm/nxp/nxp_k6x.dtsi:494 */
				#size-cells = < 0x0 >;         /* in zephyr/dts/arm/nxp/nxp_k6x.dtsi:495 */
				status = "okay";               /* in zephyr/boards/nxp/rddrone_fmuk66/rddrone_fmuk66.dts:278 */
				pinctrl-0 = < &mdio_default >; /* in zephyr/boards/nxp/rddrone_fmuk66/rddrone_fmuk66.dts:279 */
				pinctrl-names = "default";     /* in zephyr/boards/nxp/rddrone_fmuk66/rddrone_fmuk66.dts:280 */
				phandle = < 0x19 >;            /* in zephyr/dts/arm/nxp/nxp_k6x.dtsi:485 */

				/* node '/soc/ethernet@400c0000/mdio/phy@0' defined in zephyr/boards/nxp/rddrone_fmuk66/rddrone_fmuk66.dts:282 */
				phy: phy@0 {
					compatible = "ethernet-phy"; /* in zephyr/boards/nxp/rddrone_fmuk66/rddrone_fmuk66.dts:283 */
					reg = < 0x0 >;               /* in zephyr/boards/nxp/rddrone_fmuk66/rddrone_fmuk66.dts:284 */
					status = "okay";             /* in zephyr/boards/nxp/rddrone_fmuk66/rddrone_fmuk66.dts:285 */
					phandle = < 0x1c >;          /* in zephyr/boards/nxp/rddrone_fmuk66/rddrone_fmuk66.dts:273 */
				};
			};

			/* node '/soc/ethernet@400c0000/ptp_clock' defined in zephyr/dts/arm/nxp/nxp_k6x.dtsi:498 */
			enet_ptp_clock: ptp_clock {
				compatible = "nxp,enet-ptp-clock"; /* in zephyr/dts/arm/nxp/nxp_k6x.dtsi:499 */
				interrupts = < 0x52 0x0 >;         /* in zephyr/dts/arm/nxp/nxp_k6x.dtsi:500 */
				interrupt-names = "IEEE1588_TMR";  /* in zephyr/dts/arm/nxp/nxp_k6x.dtsi:501 */
				clocks = < &sim 0x10e2 0x0 0x0 >;  /* in zephyr/dts/arm/nxp/nxp_k6x.dtsi:502 */
				status = "disabled";               /* in zephyr/dts/arm/nxp/nxp_k6x.dtsi:503 */
				phandle = < 0x1a >;                /* in zephyr/dts/arm/nxp/nxp_k6x.dtsi:486 */
			};
		};

		/* node '/soc/random@40029000' defined in zephyr/dts/arm/nxp/nxp_k6x.dtsi:507 */
		rnga: random@40029000 {
			compatible = "nxp,kinetis-rnga"; /* in zephyr/dts/arm/nxp/nxp_k6x.dtsi:508 */
			reg = < 0x40029000 0x1000 >;     /* in zephyr/dts/arm/nxp/nxp_k6x.dtsi:509 */
			status = "okay";                 /* in zephyr/dts/arm/nxp/nxp_k6x.dtsi:510 */
			interrupts = < 0x17 0x0 >;       /* in zephyr/dts/arm/nxp/nxp_k6x.dtsi:511 */
		};

		/* node '/soc/can@40024000' defined in zephyr/dts/arm/nxp/nxp_k6x.dtsi:514 */
		flexcan0: can@40024000 {
			compatible = "nxp,flexcan";        /* in zephyr/dts/arm/nxp/nxp_k6x.dtsi:515 */
			reg = < 0x40024000 0x1000 >;       /* in zephyr/dts/arm/nxp/nxp_k6x.dtsi:516 */
			interrupts = < 0x4b 0x0 >,
			             < 0x4c 0x0 >,
			             < 0x4d 0x0 >,
			             < 0x4e 0x0 >,
			             < 0x4f 0x0 >,
			             < 0x50 0x0 >;         /* in zephyr/dts/arm/nxp/nxp_k6x.dtsi:517 */
			interrupt-names = "mb-0-15",
			                  "bus-off",
			                  "error",
			                  "tx-warning",
			                  "rx-warning",
			                  "wake-up";       /* in zephyr/dts/arm/nxp/nxp_k6x.dtsi:518 */
			clocks = < &sim 0x2 0x103c 0x4 >;  /* in zephyr/dts/arm/nxp/nxp_k6x.dtsi:519 */
			clk-source = < 0x1 >;              /* in zephyr/dts/arm/nxp/nxp_k6x.dtsi:520 */
			status = "okay";                   /* in zephyr/boards/nxp/rddrone_fmuk66/rddrone_fmuk66.dts:290 */
			pinctrl-0 = < &flexcan0_default >; /* in zephyr/boards/nxp/rddrone_fmuk66/rddrone_fmuk66.dts:291 */
			pinctrl-names = "default";         /* in zephyr/boards/nxp/rddrone_fmuk66/rddrone_fmuk66.dts:292 */
			phys = < &transceiver0 >;          /* in zephyr/boards/nxp/rddrone_fmuk66/rddrone_fmuk66.dts:293 */
		};

		/* node '/soc/dma-controller@40008000' defined in zephyr/dts/arm/nxp/nxp_k6x.dtsi:524 */
		edma0: dma-controller@40008000 {
			#dma-cells = < 0x2 >;             /* in zephyr/dts/arm/nxp/nxp_k6x.dtsi:525 */
			compatible = "nxp,mcux-edma";     /* in zephyr/dts/arm/nxp/nxp_k6x.dtsi:526 */
			nxp,version = < 0x2 >;            /* in zephyr/dts/arm/nxp/nxp_k6x.dtsi:527 */
			dma-channels = < 0x10 >;          /* in zephyr/dts/arm/nxp/nxp_k6x.dtsi:528 */
			dma-requests = < 0x40 >;          /* in zephyr/dts/arm/nxp/nxp_k6x.dtsi:529 */
			nxp,mem2mem;                      /* in zephyr/dts/arm/nxp/nxp_k6x.dtsi:530 */
			reg = < 0x40008000 0x1000 >,
			      < 0x40021000 0x1000 >;      /* in zephyr/dts/arm/nxp/nxp_k6x.dtsi:531 */
			interrupts = < 0x0 0x0 >,
			             < 0x1 0x0 >,
			             < 0x2 0x0 >,
			             < 0x3 0x0 >,
			             < 0x4 0x0 >,
			             < 0x5 0x0 >,
			             < 0x6 0x0 >,
			             < 0x7 0x0 >,
			             < 0x8 0x0 >,
			             < 0x9 0x0 >,
			             < 0xa 0x0 >,
			             < 0xb 0x0 >,
			             < 0xc 0x0 >,
			             < 0xd 0x0 >,
			             < 0xe 0x0 >,
			             < 0xf 0x0 >,
			             < 0x10 0x0 >;        /* in zephyr/dts/arm/nxp/nxp_k6x.dtsi:533 */
			clocks = < &sim 0x0 0x1040 0x2 >,
			         < &sim 0x2 0x103c 0x2 >; /* in zephyr/dts/arm/nxp/nxp_k6x.dtsi:538 */
			status = "okay";                  /* in zephyr/boards/nxp/rddrone_fmuk66/rddrone_fmuk66.dts:386 */
			phandle = < 0xf >;                /* in zephyr/dts/arm/nxp/nxp_k6x.dtsi:340 */
		};

		/* node '/soc/pit@40037000' defined in zephyr/dts/arm/nxp/nxp_k6x.dtsi:543 */
		pit0: pit@40037000 {
			compatible = "nxp,pit";            /* in zephyr/dts/arm/nxp/nxp_k6x.dtsi:544 */
			reg = < 0x40037000 0x1000 >;       /* in zephyr/dts/arm/nxp/nxp_k6x.dtsi:545 */
			clocks = < &sim 0x2 0x103c 0x17 >; /* in zephyr/dts/arm/nxp/nxp_k6x.dtsi:546 */
			max-load-value = < 0xffffffff >;   /* in zephyr/dts/arm/nxp/nxp_k6x.dtsi:548 */
			#address-cells = < 0x1 >;          /* in zephyr/dts/arm/nxp/nxp_k6x.dtsi:549 */
			#size-cells = < 0x0 >;             /* in zephyr/dts/arm/nxp/nxp_k6x.dtsi:550 */
			status = "okay";                   /* in zephyr/boards/nxp/rddrone_fmuk66/rddrone_fmuk66.dts:390 */

			/* node '/soc/pit@40037000/pit0_channel@0' defined in zephyr/dts/arm/nxp/nxp_k6x.dtsi:552 */
			pit0_channel0: pit0_channel@0 {
				compatible = "nxp,pit-channel"; /* in zephyr/dts/arm/nxp/nxp_k6x.dtsi:553 */
				reg = < 0x0 >;                  /* in zephyr/dts/arm/nxp/nxp_k6x.dtsi:554 */
				interrupts = < 0x30 0x0 >;      /* in zephyr/dts/arm/nxp/nxp_k6x.dtsi:555 */
				status = "disabled";            /* in zephyr/dts/arm/nxp/nxp_k6x.dtsi:556 */
			};

			/* node '/soc/pit@40037000/pit0_channel@1' defined in zephyr/dts/arm/nxp/nxp_k6x.dtsi:559 */
			pit0_channel1: pit0_channel@1 {
				compatible = "nxp,pit-channel"; /* in zephyr/dts/arm/nxp/nxp_k6x.dtsi:560 */
				reg = < 0x1 >;                  /* in zephyr/dts/arm/nxp/nxp_k6x.dtsi:561 */
				interrupts = < 0x31 0x0 >;      /* in zephyr/dts/arm/nxp/nxp_k6x.dtsi:562 */
				status = "disabled";            /* in zephyr/dts/arm/nxp/nxp_k6x.dtsi:563 */
			};

			/* node '/soc/pit@40037000/pit0_channel@2' defined in zephyr/dts/arm/nxp/nxp_k6x.dtsi:566 */
			pit0_channel2: pit0_channel@2 {
				compatible = "nxp,pit-channel"; /* in zephyr/dts/arm/nxp/nxp_k6x.dtsi:567 */
				reg = < 0x2 >;                  /* in zephyr/dts/arm/nxp/nxp_k6x.dtsi:568 */
				interrupts = < 0x32 0x0 >;      /* in zephyr/dts/arm/nxp/nxp_k6x.dtsi:569 */
				status = "disabled";            /* in zephyr/dts/arm/nxp/nxp_k6x.dtsi:570 */
			};

			/* node '/soc/pit@40037000/pit0_channel@3' defined in zephyr/dts/arm/nxp/nxp_k6x.dtsi:573 */
			pit0_channel3: pit0_channel@3 {
				compatible = "nxp,pit-channel"; /* in zephyr/dts/arm/nxp/nxp_k6x.dtsi:574 */
				reg = < 0x3 >;                  /* in zephyr/dts/arm/nxp/nxp_k6x.dtsi:575 */
				interrupts = < 0x33 0x0 >;      /* in zephyr/dts/arm/nxp/nxp_k6x.dtsi:576 */
				status = "disabled";            /* in zephyr/dts/arm/nxp/nxp_k6x.dtsi:577 */
			};
		};

		/* node '/soc/lpuart@400c4000' defined in zephyr/dts/arm/nxp/nxp_k66.dtsi:17 */
		lpuart0: lpuart@400c4000 {
			compatible = "nxp,lpuart";         /* in zephyr/dts/arm/nxp/nxp_k66.dtsi:18 */
			reg = < 0x400c4000 0x14 >;         /* in zephyr/dts/arm/nxp/nxp_k66.dtsi:19 */
			interrupts = < 0x56 0x0 >;         /* in zephyr/dts/arm/nxp/nxp_k66.dtsi:20 */
			clocks = < &sim 0x0 0x1038 0x14 >; /* in zephyr/dts/arm/nxp/nxp_k66.dtsi:21 */
			dmas = < &edma0 0x1 0x3a >,
			       < &edma0 0x2 0x3b >;        /* in zephyr/dts/arm/nxp/nxp_k66.dtsi:22 */
			dma-names = "rx",
			            "tx";                  /* in zephyr/dts/arm/nxp/nxp_k66.dtsi:23 */
			status = "okay";                   /* in zephyr/boards/nxp/rddrone_fmuk66/rddrone_fmuk66.dts:169 */
			current-speed = < 0x1c200 >;       /* in zephyr/boards/nxp/rddrone_fmuk66/rddrone_fmuk66.dts:170 */
			pinctrl-0 = < &lpuart0_default >;  /* in zephyr/boards/nxp/rddrone_fmuk66/rddrone_fmuk66.dts:171 */
			pinctrl-names = "default";         /* in zephyr/boards/nxp/rddrone_fmuk66/rddrone_fmuk66.dts:172 */
		};

		/* node '/soc/can@400a4000' defined in zephyr/dts/arm/nxp/nxp_k66.dtsi:27 */
		flexcan1: can@400a4000 {
			compatible = "nxp,flexcan";        /* in zephyr/dts/arm/nxp/nxp_k66.dtsi:28 */
			reg = < 0x400a4000 0x1000 >;       /* in zephyr/dts/arm/nxp/nxp_k66.dtsi:29 */
			interrupts = < 0x5e 0x0 >,
			             < 0x5f 0x0 >,
			             < 0x60 0x0 >,
			             < 0x61 0x0 >,
			             < 0x62 0x0 >,
			             < 0x63 0x0 >;         /* in zephyr/dts/arm/nxp/nxp_k66.dtsi:30 */
			interrupt-names = "mb-0-15",
			                  "bus-off",
			                  "error",
			                  "tx-warning",
			                  "rx-warning",
			                  "wake-up";       /* in zephyr/dts/arm/nxp/nxp_k66.dtsi:31 */
			clocks = < &sim 0x2 0x1030 0x4 >;  /* in zephyr/dts/arm/nxp/nxp_k66.dtsi:33 */
			clk-source = < 0x1 >;              /* in zephyr/dts/arm/nxp/nxp_k66.dtsi:34 */
			status = "okay";                   /* in zephyr/boards/nxp/rddrone_fmuk66/rddrone_fmuk66.dts:297 */
			pinctrl-0 = < &flexcan1_default >; /* in zephyr/boards/nxp/rddrone_fmuk66/rddrone_fmuk66.dts:298 */
			pinctrl-names = "default";         /* in zephyr/boards/nxp/rddrone_fmuk66/rddrone_fmuk66.dts:299 */
			phys = < &transceiver1 >;          /* in zephyr/boards/nxp/rddrone_fmuk66/rddrone_fmuk66.dts:300 */
		};
	};

	/* node '/cpus' defined in zephyr/dts/arm/nxp/nxp_k6x.dtsi:22 */
	cpus {
		#address-cells = < 0x1 >; /* in zephyr/dts/arm/nxp/nxp_k6x.dtsi:23 */
		#size-cells = < 0x0 >;    /* in zephyr/dts/arm/nxp/nxp_k6x.dtsi:24 */

		/* node '/cpus/cpu@0' defined in zephyr/dts/arm/nxp/nxp_k6x.dtsi:26 */
		cpu0: cpu@0 {
			device_type = "cpu";             /* in zephyr/dts/arm/nxp/nxp_k6x.dtsi:27 */
			compatible = "arm,cortex-m4f";   /* in zephyr/dts/arm/nxp/nxp_k6x.dtsi:28 */
			reg = < 0x0 >;                   /* in zephyr/dts/arm/nxp/nxp_k6x.dtsi:29 */
			clock-frequency = < 0x9896800 >; /* in zephyr/boards/nxp/rddrone_fmuk66/rddrone_fmuk66.dts:127 */
		};
	};

	/* node '/memory@1fff0000' defined in zephyr/dts/arm/nxp/nxp_k6x.dtsi:42 */
	sram_l: memory@1fff0000 {
		compatible = "zephyr,memory-region",
		             "mmio-sram";            /* in zephyr/dts/arm/nxp/nxp_k6x.dtsi:43 */
		reg = < 0x1fff0000 0x10000 >;        /* in zephyr/dts/arm/nxp/nxp_k6x.dtsi:44 */
		zephyr,memory-region = "SRAML";      /* in zephyr/dts/arm/nxp/nxp_k6x.dtsi:45 */
	};

	/* node '/memory@20000000' defined in zephyr/dts/arm/nxp/nxp_k6x.dtsi:48 */
	sram0: memory@20000000 {
		compatible = "mmio-sram";     /* in zephyr/dts/arm/nxp/nxp_k6x.dtsi:49 */
		reg = < 0x20000000 0x30000 >; /* in zephyr/dts/arm/nxp/nxp_k6x.dtsi:50 */
	};

	/* node '/temp0' defined in zephyr/dts/arm/nxp/nxp_k6x.dtsi:53 */
	temp0: temp0 {
		compatible = "nxp,kinetis-temperature"; /* in zephyr/dts/arm/nxp/nxp_k6x.dtsi:54 */
		io-channels = < &adc0 0x1a >,
		              < &adc0 0x1b >;           /* in zephyr/dts/arm/nxp/nxp_k6x.dtsi:55 */
		io-channel-names = "SENSOR",
		                   "BANDGAP";           /* in zephyr/dts/arm/nxp/nxp_k6x.dtsi:56 */
		bandgap-voltage = < 0xf4240 >;          /* in zephyr/dts/arm/nxp/nxp_k6x.dtsi:57 */
		vtemp25 = < 0xaece0 >;                  /* in zephyr/dts/arm/nxp/nxp_k6x.dtsi:58 */
		sensor-slope-cold = < 0x654 >;          /* in zephyr/dts/arm/nxp/nxp_k6x.dtsi:59 */
		sensor-slope-hot = < 0x654 >;           /* in zephyr/dts/arm/nxp/nxp_k6x.dtsi:60 */
		status = "disabled";                    /* in zephyr/dts/arm/nxp/nxp_k6x.dtsi:61 */
	};

	/* node '/temp1' defined in zephyr/dts/arm/nxp/nxp_k6x.dtsi:64 */
	temp1: temp1 {
		compatible = "nxp,kinetis-temperature"; /* in zephyr/dts/arm/nxp/nxp_k6x.dtsi:65 */
		io-channels = < &adc1 0x1a >,
		              < &adc1 0x1b >;           /* in zephyr/dts/arm/nxp/nxp_k6x.dtsi:66 */
		io-channel-names = "SENSOR",
		                   "BANDGAP";           /* in zephyr/dts/arm/nxp/nxp_k6x.dtsi:67 */
		bandgap-voltage = < 0xf4240 >;          /* in zephyr/dts/arm/nxp/nxp_k6x.dtsi:68 */
		vtemp25 = < 0xaece0 >;                  /* in zephyr/dts/arm/nxp/nxp_k6x.dtsi:69 */
		sensor-slope-cold = < 0x654 >;          /* in zephyr/dts/arm/nxp/nxp_k6x.dtsi:70 */
		sensor-slope-hot = < 0x654 >;           /* in zephyr/dts/arm/nxp/nxp_k6x.dtsi:71 */
		status = "okay";                        /* in zephyr/boards/nxp/rddrone_fmuk66/rddrone_fmuk66.dts:139 */
	};

	/* node '/pinctrl' defined in zephyr/dts/arm/nxp/nxp_k6x.dtsi:76 */
	pinctrl: pinctrl {
		compatible = "nxp,port-pinctrl"; /* in zephyr/dts/arm/nxp/nxp_k6x.dtsi:77 */
		status = "okay";                 /* in zephyr/dts/arm/nxp/nxp_k6x.dtsi:78 */

		/* node '/pinctrl/mdio_default' defined in zephyr/boards/nxp/rddrone_fmuk66/rddrone_fmuk66-pinctrl.dtsi:12 */
		mdio_default: mdio_default {
			phandle = < 0x1d >; /* in zephyr/boards/nxp/rddrone_fmuk66/rddrone_fmuk66.dts:279 */

			/* node '/pinctrl/mdio_default/group0' defined in zephyr/boards/nxp/rddrone_fmuk66/rddrone_fmuk66-pinctrl.dtsi:13 */
			group0 {
				pinmux = < 0x10000400 >; /* in zephyr/boards/nxp/rddrone_fmuk66/rddrone_fmuk66-pinctrl.dtsi:14 */
				drive-strength = "low";  /* in zephyr/boards/nxp/rddrone_fmuk66/rddrone_fmuk66-pinctrl.dtsi:15 */
				drive-open-drain;        /* in zephyr/boards/nxp/rddrone_fmuk66/rddrone_fmuk66-pinctrl.dtsi:16 */
				bias-pull-up;            /* in zephyr/boards/nxp/rddrone_fmuk66/rddrone_fmuk66-pinctrl.dtsi:17 */
				slew-rate = "fast";      /* in zephyr/boards/nxp/rddrone_fmuk66/rddrone_fmuk66-pinctrl.dtsi:18 */
			};

			/* node '/pinctrl/mdio_default/group1' defined in zephyr/boards/nxp/rddrone_fmuk66/rddrone_fmuk66-pinctrl.dtsi:21 */
			group1 {
				pinmux = < 0x10400400 >; /* in zephyr/boards/nxp/rddrone_fmuk66/rddrone_fmuk66-pinctrl.dtsi:22 */
				drive-strength = "low";  /* in zephyr/boards/nxp/rddrone_fmuk66/rddrone_fmuk66-pinctrl.dtsi:23 */
				slew-rate = "fast";      /* in zephyr/boards/nxp/rddrone_fmuk66/rddrone_fmuk66-pinctrl.dtsi:24 */
			};
		};

		/* node '/pinctrl/enet_default' defined in zephyr/boards/nxp/rddrone_fmuk66/rddrone_fmuk66-pinctrl.dtsi:28 */
		enet_default: enet_default {
			phandle = < 0x1b >; /* in zephyr/boards/nxp/rddrone_fmuk66/rddrone_fmuk66.dts:270 */

			/* node '/pinctrl/enet_default/group0' defined in zephyr/boards/nxp/rddrone_fmuk66/rddrone_fmuk66-pinctrl.dtsi:29 */
			group0 {
				pinmux = < 0x1400400 >,
				         < 0x3000400 >,
				         < 0x3400400 >,
				         < 0x3800400 >,
				         < 0x3c00400 >,
				         < 0x4400400 >,
				         < 0x4000400 >; /* in zephyr/boards/nxp/rddrone_fmuk66/rddrone_fmuk66-pinctrl.dtsi:30 */
				drive-strength = "low"; /* in zephyr/boards/nxp/rddrone_fmuk66/rddrone_fmuk66-pinctrl.dtsi:37 */
				slew-rate = "fast";     /* in zephyr/boards/nxp/rddrone_fmuk66/rddrone_fmuk66-pinctrl.dtsi:38 */
			};
		};

		/* node '/pinctrl/flexcan0_default' defined in zephyr/boards/nxp/rddrone_fmuk66/rddrone_fmuk66-pinctrl.dtsi:42 */
		flexcan0_default: flexcan0_default {
			phandle = < 0x1e >; /* in zephyr/boards/nxp/rddrone_fmuk66/rddrone_fmuk66.dts:291 */

			/* node '/pinctrl/flexcan0_default/group0' defined in zephyr/boards/nxp/rddrone_fmuk66/rddrone_fmuk66-pinctrl.dtsi:43 */
			group0 {
				pinmux = < 0x14c00200 >,
				         < 0x14800200 >; /* in zephyr/boards/nxp/rddrone_fmuk66/rddrone_fmuk66-pinctrl.dtsi:44 */
				drive-strength = "low";  /* in zephyr/boards/nxp/rddrone_fmuk66/rddrone_fmuk66-pinctrl.dtsi:46 */
				slew-rate = "fast";      /* in zephyr/boards/nxp/rddrone_fmuk66/rddrone_fmuk66-pinctrl.dtsi:47 */
			};
		};

		/* node '/pinctrl/flexcan1_default' defined in zephyr/boards/nxp/rddrone_fmuk66/rddrone_fmuk66-pinctrl.dtsi:51 */
		flexcan1_default: flexcan1_default {
			phandle = < 0x21 >; /* in zephyr/boards/nxp/rddrone_fmuk66/rddrone_fmuk66.dts:298 */

			/* node '/pinctrl/flexcan1_default/group0' defined in zephyr/boards/nxp/rddrone_fmuk66/rddrone_fmuk66-pinctrl.dtsi:52 */
			group0 {
				pinmux = < 0x24000200 >,
				         < 0x24400200 >; /* in zephyr/boards/nxp/rddrone_fmuk66/rddrone_fmuk66-pinctrl.dtsi:53 */
				drive-strength = "low";  /* in zephyr/boards/nxp/rddrone_fmuk66/rddrone_fmuk66-pinctrl.dtsi:55 */
				slew-rate = "fast";      /* in zephyr/boards/nxp/rddrone_fmuk66/rddrone_fmuk66-pinctrl.dtsi:56 */
			};
		};

		/* node '/pinctrl/ftm0_default' defined in zephyr/boards/nxp/rddrone_fmuk66/rddrone_fmuk66-pinctrl.dtsi:60 */
		ftm0_default: ftm0_default {
			phandle = < 0x17 >; /* in zephyr/boards/nxp/rddrone_fmuk66/rddrone_fmuk66.dts:152 */

			/* node '/pinctrl/ftm0_default/group0' defined in zephyr/boards/nxp/rddrone_fmuk66/rddrone_fmuk66-pinctrl.dtsi:61 */
			group0 {
				pinmux = < 0x20400400 >,
				         < 0x1800300 >,
				         < 0x31000400 >,
				         < 0x31400400 >; /* in zephyr/boards/nxp/rddrone_fmuk66/rddrone_fmuk66-pinctrl.dtsi:62 */
				drive-strength = "low";  /* in zephyr/boards/nxp/rddrone_fmuk66/rddrone_fmuk66-pinctrl.dtsi:66 */
				slew-rate = "fast";      /* in zephyr/boards/nxp/rddrone_fmuk66/rddrone_fmuk66-pinctrl.dtsi:67 */
			};
		};

		/* node '/pinctrl/ftm3_default' defined in zephyr/boards/nxp/rddrone_fmuk66/rddrone_fmuk66-pinctrl.dtsi:72 */
		ftm3_default: ftm3_default {
			phandle = < 0x18 >; /* in zephyr/boards/nxp/rddrone_fmuk66/rddrone_fmuk66.dts:162 */

			/* node '/pinctrl/ftm3_default/group0' defined in zephyr/boards/nxp/rddrone_fmuk66/rddrone_fmuk66-pinctrl.dtsi:73 */
			group0 {
				pinmux = < 0x30400400 >,
				         < 0x22000300 >,
				         < 0x22400300 >,
				         < 0x42c00600 >,
				         < 0x43000600 >; /* in zephyr/boards/nxp/rddrone_fmuk66/rddrone_fmuk66-pinctrl.dtsi:74 */
				drive-strength = "low";  /* in zephyr/boards/nxp/rddrone_fmuk66/rddrone_fmuk66-pinctrl.dtsi:79 */
				slew-rate = "fast";      /* in zephyr/boards/nxp/rddrone_fmuk66/rddrone_fmuk66-pinctrl.dtsi:80 */
			};
		};

		/* node '/pinctrl/i2c0_default' defined in zephyr/boards/nxp/rddrone_fmuk66/rddrone_fmuk66-pinctrl.dtsi:84 */
		i2c0_default: i2c0_default {
			phandle = < 0x4 >; /* in zephyr/boards/nxp/rddrone_fmuk66/rddrone_fmuk66.dts:306 */

			/* node '/pinctrl/i2c0_default/group0' defined in zephyr/boards/nxp/rddrone_fmuk66/rddrone_fmuk66-pinctrl.dtsi:85 */
			group0 {
				pinmux = < 0x46000500 >; /* in zephyr/boards/nxp/rddrone_fmuk66/rddrone_fmuk66-pinctrl.dtsi:86 */
				drive-strength = "low";  /* in zephyr/boards/nxp/rddrone_fmuk66/rddrone_fmuk66-pinctrl.dtsi:87 */
				slew-rate = "fast";      /* in zephyr/boards/nxp/rddrone_fmuk66/rddrone_fmuk66-pinctrl.dtsi:88 */
			};

			/* node '/pinctrl/i2c0_default/group1' defined in zephyr/boards/nxp/rddrone_fmuk66/rddrone_fmuk66-pinctrl.dtsi:91 */
			group1 {
				pinmux = < 0x46400500 >; /* in zephyr/boards/nxp/rddrone_fmuk66/rddrone_fmuk66-pinctrl.dtsi:92 */
				drive-strength = "low";  /* in zephyr/boards/nxp/rddrone_fmuk66/rddrone_fmuk66-pinctrl.dtsi:93 */
				slew-rate = "fast";      /* in zephyr/boards/nxp/rddrone_fmuk66/rddrone_fmuk66-pinctrl.dtsi:94 */
				drive-open-drain;        /* in zephyr/boards/nxp/rddrone_fmuk66/rddrone_fmuk66-pinctrl.dtsi:95 */
			};
		};

		/* node '/pinctrl/i2c1_default' defined in zephyr/boards/nxp/rddrone_fmuk66/rddrone_fmuk66-pinctrl.dtsi:99 */
		i2c1_default: i2c1_default {
			phandle = < 0x5 >; /* in zephyr/boards/nxp/rddrone_fmuk66/rddrone_fmuk66.dts:315 */

			/* node '/pinctrl/i2c1_default/group0' defined in zephyr/boards/nxp/rddrone_fmuk66/rddrone_fmuk66-pinctrl.dtsi:100 */
			group0 {
				pinmux = < 0x22800200 >; /* in zephyr/boards/nxp/rddrone_fmuk66/rddrone_fmuk66-pinctrl.dtsi:101 */
				drive-strength = "low";  /* in zephyr/boards/nxp/rddrone_fmuk66/rddrone_fmuk66-pinctrl.dtsi:102 */
				slew-rate = "fast";      /* in zephyr/boards/nxp/rddrone_fmuk66/rddrone_fmuk66-pinctrl.dtsi:103 */
			};

			/* node '/pinctrl/i2c1_default/group1' defined in zephyr/boards/nxp/rddrone_fmuk66/rddrone_fmuk66-pinctrl.dtsi:106 */
			group1 {
				pinmux = < 0x22c00200 >; /* in zephyr/boards/nxp/rddrone_fmuk66/rddrone_fmuk66-pinctrl.dtsi:107 */
				drive-strength = "low";  /* in zephyr/boards/nxp/rddrone_fmuk66/rddrone_fmuk66-pinctrl.dtsi:108 */
				slew-rate = "fast";      /* in zephyr/boards/nxp/rddrone_fmuk66/rddrone_fmuk66-pinctrl.dtsi:109 */
				drive-open-drain;        /* in zephyr/boards/nxp/rddrone_fmuk66/rddrone_fmuk66-pinctrl.dtsi:110 */
			};
		};

		/* node '/pinctrl/lpuart0_default' defined in zephyr/boards/nxp/rddrone_fmuk66/rddrone_fmuk66-pinctrl.dtsi:114 */
		lpuart0_default: lpuart0_default {
			phandle = < 0x20 >; /* in zephyr/boards/nxp/rddrone_fmuk66/rddrone_fmuk66.dts:171 */

			/* node '/pinctrl/lpuart0_default/group0' defined in zephyr/boards/nxp/rddrone_fmuk66/rddrone_fmuk66-pinctrl.dtsi:115 */
			group0 {
				pinmux = < 0x32000500 >; /* in zephyr/boards/nxp/rddrone_fmuk66/rddrone_fmuk66-pinctrl.dtsi:116 */
				drive-strength = "low";  /* in zephyr/boards/nxp/rddrone_fmuk66/rddrone_fmuk66-pinctrl.dtsi:117 */
				bias-pull-up;            /* in zephyr/boards/nxp/rddrone_fmuk66/rddrone_fmuk66-pinctrl.dtsi:118 */
				slew-rate = "fast";      /* in zephyr/boards/nxp/rddrone_fmuk66/rddrone_fmuk66-pinctrl.dtsi:119 */
			};

			/* node '/pinctrl/lpuart0_default/group1' defined in zephyr/boards/nxp/rddrone_fmuk66/rddrone_fmuk66-pinctrl.dtsi:122 */
			group1 {
				pinmux = < 0x32400500 >; /* in zephyr/boards/nxp/rddrone_fmuk66/rddrone_fmuk66-pinctrl.dtsi:123 */
				drive-strength = "low";  /* in zephyr/boards/nxp/rddrone_fmuk66/rddrone_fmuk66-pinctrl.dtsi:124 */
				slew-rate = "fast";      /* in zephyr/boards/nxp/rddrone_fmuk66/rddrone_fmuk66-pinctrl.dtsi:125 */
			};
		};

		/* node '/pinctrl/spi0_default' defined in zephyr/boards/nxp/rddrone_fmuk66/rddrone_fmuk66-pinctrl.dtsi:129 */
		spi0_default: spi0_default {
			phandle = < 0x10 >; /* in zephyr/boards/nxp/rddrone_fmuk66/rddrone_fmuk66.dts:339 */

			/* node '/pinctrl/spi0_default/group0' defined in zephyr/boards/nxp/rddrone_fmuk66/rddrone_fmuk66-pinctrl.dtsi:130 */
			group0 {
				pinmux = < 0x20800200 >,
				         < 0x21400200 >,
				         < 0x21c00200 >,
				         < 0x21800200 >; /* in zephyr/boards/nxp/rddrone_fmuk66/rddrone_fmuk66-pinctrl.dtsi:131 */
				drive-strength = "low";  /* in zephyr/boards/nxp/rddrone_fmuk66/rddrone_fmuk66-pinctrl.dtsi:135 */
				slew-rate = "fast";      /* in zephyr/boards/nxp/rddrone_fmuk66/rddrone_fmuk66-pinctrl.dtsi:136 */
			};
		};

		/* node '/pinctrl/spi1_default' defined in zephyr/boards/nxp/rddrone_fmuk66/rddrone_fmuk66-pinctrl.dtsi:140 */
		spi1_default: spi1_default {
			phandle = < 0x11 >; /* in zephyr/boards/nxp/rddrone_fmuk66/rddrone_fmuk66.dts:346 */

			/* node '/pinctrl/spi1_default/group0' defined in zephyr/boards/nxp/rddrone_fmuk66/rddrone_fmuk66-pinctrl.dtsi:141 */
			group0 {
				pinmux = < 0x12800200 >,
				         < 0x12400200 >,
				         < 0x12c00200 >,
				         < 0x14400200 >,
				         < 0x14000200 >; /* in zephyr/boards/nxp/rddrone_fmuk66/rddrone_fmuk66-pinctrl.dtsi:142 */
				drive-strength = "low";  /* in zephyr/boards/nxp/rddrone_fmuk66/rddrone_fmuk66-pinctrl.dtsi:147 */
				slew-rate = "fast";      /* in zephyr/boards/nxp/rddrone_fmuk66/rddrone_fmuk66-pinctrl.dtsi:148 */
			};
		};

		/* node '/pinctrl/spi2_default' defined in zephyr/boards/nxp/rddrone_fmuk66/rddrone_fmuk66-pinctrl.dtsi:152 */
		spi2_default: spi2_default {
			phandle = < 0x16 >; /* in zephyr/boards/nxp/rddrone_fmuk66/rddrone_fmuk66.dts:381 */

			/* node '/pinctrl/spi2_default/group0' defined in zephyr/boards/nxp/rddrone_fmuk66/rddrone_fmuk66-pinctrl.dtsi:153 */
			group0 {
				pinmux = < 0x15000200 >,
				         < 0x15400200 >,
				         < 0x15c00200 >,
				         < 0x15800200 >; /* in zephyr/boards/nxp/rddrone_fmuk66/rddrone_fmuk66-pinctrl.dtsi:154 */
				drive-strength = "low";  /* in zephyr/boards/nxp/rddrone_fmuk66/rddrone_fmuk66-pinctrl.dtsi:158 */
				slew-rate = "fast";      /* in zephyr/boards/nxp/rddrone_fmuk66/rddrone_fmuk66-pinctrl.dtsi:159 */
			};
		};

		/* node '/pinctrl/uart0_default' defined in zephyr/boards/nxp/rddrone_fmuk66/rddrone_fmuk66-pinctrl.dtsi:163 */
		uart0_default: uart0_default {
			phandle = < 0x6 >; /* in zephyr/boards/nxp/rddrone_fmuk66/rddrone_fmuk66.dts:184 */

			/* node '/pinctrl/uart0_default/group0' defined in zephyr/boards/nxp/rddrone_fmuk66/rddrone_fmuk66-pinctrl.dtsi:164 */
			group0 {
				pinmux = < 0x400200 >,
				         < 0x800200 >;  /* in zephyr/boards/nxp/rddrone_fmuk66/rddrone_fmuk66-pinctrl.dtsi:165 */
				drive-strength = "low"; /* in zephyr/boards/nxp/rddrone_fmuk66/rddrone_fmuk66-pinctrl.dtsi:167 */
				slew-rate = "fast";     /* in zephyr/boards/nxp/rddrone_fmuk66/rddrone_fmuk66-pinctrl.dtsi:168 */
			};
		};

		/* node '/pinctrl/uart1_default' defined in zephyr/boards/nxp/rddrone_fmuk66/rddrone_fmuk66-pinctrl.dtsi:172 */
		uart1_default: uart1_default {
			phandle = < 0x7 >; /* in zephyr/boards/nxp/rddrone_fmuk66/rddrone_fmuk66.dts:191 */

			/* node '/pinctrl/uart1_default/group0' defined in zephyr/boards/nxp/rddrone_fmuk66/rddrone_fmuk66-pinctrl.dtsi:173 */
			group0 {
				pinmux = < 0x20c00300 >,
				         < 0x21000300 >; /* in zephyr/boards/nxp/rddrone_fmuk66/rddrone_fmuk66-pinctrl.dtsi:174 */
				drive-strength = "low";  /* in zephyr/boards/nxp/rddrone_fmuk66/rddrone_fmuk66-pinctrl.dtsi:176 */
				slew-rate = "fast";      /* in zephyr/boards/nxp/rddrone_fmuk66/rddrone_fmuk66-pinctrl.dtsi:177 */
			};
		};

		/* node '/pinctrl/uart2_default' defined in zephyr/boards/nxp/rddrone_fmuk66/rddrone_fmuk66-pinctrl.dtsi:182 */
		uart2_default: uart2_default {
			phandle = < 0x8 >; /* in zephyr/boards/nxp/rddrone_fmuk66/rddrone_fmuk66.dts:198 */

			/* node '/pinctrl/uart2_default/group0' defined in zephyr/boards/nxp/rddrone_fmuk66/rddrone_fmuk66-pinctrl.dtsi:183 */
			group0 {
				pinmux = < 0x30800300 >,
				         < 0x30c00300 >; /* in zephyr/boards/nxp/rddrone_fmuk66/rddrone_fmuk66-pinctrl.dtsi:184 */
				drive-strength = "low";  /* in zephyr/boards/nxp/rddrone_fmuk66/rddrone_fmuk66-pinctrl.dtsi:186 */
				slew-rate = "fast";      /* in zephyr/boards/nxp/rddrone_fmuk66/rddrone_fmuk66-pinctrl.dtsi:187 */
			};
		};

		/* node '/pinctrl/uart4_default' defined in zephyr/boards/nxp/rddrone_fmuk66/rddrone_fmuk66-pinctrl.dtsi:191 */
		uart4_default: uart4_default {
			phandle = < 0x9 >; /* in zephyr/boards/nxp/rddrone_fmuk66/rddrone_fmuk66.dts:205 */

			/* node '/pinctrl/uart4_default/group0' defined in zephyr/boards/nxp/rddrone_fmuk66/rddrone_fmuk66-pinctrl.dtsi:192 */
			group0 {
				pinmux = < 0x23400300 >,
				         < 0x46c00300 >,
				         < 0x23800300 >,
				         < 0x23c00300 >; /* in zephyr/boards/nxp/rddrone_fmuk66/rddrone_fmuk66-pinctrl.dtsi:193 */
				drive-strength = "low";  /* in zephyr/boards/nxp/rddrone_fmuk66/rddrone_fmuk66-pinctrl.dtsi:197 */
				slew-rate = "fast";      /* in zephyr/boards/nxp/rddrone_fmuk66/rddrone_fmuk66-pinctrl.dtsi:198 */
			};
		};
	};

	/* node '/leds' defined in zephyr/boards/nxp/rddrone_fmuk66/rddrone_fmuk66.dts:48 */
	leds {
		compatible = "gpio-leds"; /* in zephyr/boards/nxp/rddrone_fmuk66/rddrone_fmuk66.dts:49 */

		/* node '/leds/led_0' defined in zephyr/boards/nxp/rddrone_fmuk66/rddrone_fmuk66.dts:51 */
		amber_led: led_0 {
			gpios = < &gpiod 0xd 0x1 >; /* in zephyr/boards/nxp/rddrone_fmuk66/rddrone_fmuk66.dts:52 */
			label = "LED_AMB";          /* in zephyr/boards/nxp/rddrone_fmuk66/rddrone_fmuk66.dts:53 */
		};

		/* node '/leds/led_1' defined in zephyr/boards/nxp/rddrone_fmuk66/rddrone_fmuk66.dts:56 */
		green_led: led_1 {
			gpios = < &gpiod 0xe 0x1 >; /* in zephyr/boards/nxp/rddrone_fmuk66/rddrone_fmuk66.dts:57 */
			label = "LED_GRN";          /* in zephyr/boards/nxp/rddrone_fmuk66/rddrone_fmuk66.dts:58 */
		};
	};

	/* node '/pwmleds' defined in zephyr/boards/nxp/rddrone_fmuk66/rddrone_fmuk66.dts:62 */
	pwmleds {
		compatible = "pwm-leds"; /* in zephyr/boards/nxp/rddrone_fmuk66/rddrone_fmuk66.dts:63 */

		/* node '/pwmleds/red_pwm_led' defined in zephyr/boards/nxp/rddrone_fmuk66/rddrone_fmuk66.dts:65 */
		red_pwm_led: red_pwm_led {
			pwms = < &ftm3 0x1 0xee6b28 0x1 >; /* in zephyr/boards/nxp/rddrone_fmuk66/rddrone_fmuk66.dts:66 */
		};

		/* node '/pwmleds/blue_pwm_led' defined in zephyr/boards/nxp/rddrone_fmuk66/rddrone_fmuk66.dts:69 */
		blue_pwm_led: blue_pwm_led {
			pwms = < &ftm3 0x4 0xee6b28 0x1 >; /* in zephyr/boards/nxp/rddrone_fmuk66/rddrone_fmuk66.dts:70 */
		};

		/* node '/pwmleds/green_pwm_led' defined in zephyr/boards/nxp/rddrone_fmuk66/rddrone_fmuk66.dts:73 */
		green_pwm_led: green_pwm_led {
			pwms = < &ftm3 0x5 0xee6b28 0x1 >; /* in zephyr/boards/nxp/rddrone_fmuk66/rddrone_fmuk66.dts:74 */
		};
	};

	/* node '/can-phy0' defined in zephyr/boards/nxp/rddrone_fmuk66/rddrone_fmuk66.dts:78 */
	transceiver0: can-phy0 {
		compatible = "nxp,tja1042",
		             "can-transceiver-gpio"; /* in zephyr/boards/nxp/rddrone_fmuk66/rddrone_fmuk66.dts:79 */
		max-bitrate = < 0x4c4b40 >;          /* in zephyr/boards/nxp/rddrone_fmuk66/rddrone_fmuk66.dts:80 */
		standby-gpios = < &gpioc 0x13 0x0 >; /* in zephyr/boards/nxp/rddrone_fmuk66/rddrone_fmuk66.dts:81 */
		#phy-cells = < 0x0 >;                /* in zephyr/boards/nxp/rddrone_fmuk66/rddrone_fmuk66.dts:82 */
		phandle = < 0x1f >;                  /* in zephyr/boards/nxp/rddrone_fmuk66/rddrone_fmuk66.dts:293 */
	};

	/* node '/can-phy1' defined in zephyr/boards/nxp/rddrone_fmuk66/rddrone_fmuk66.dts:85 */
	transceiver1: can-phy1 {
		compatible = "nxp,tja1042",
		             "can-transceiver-gpio"; /* in zephyr/boards/nxp/rddrone_fmuk66/rddrone_fmuk66.dts:86 */
		max-bitrate = < 0x4c4b40 >;          /* in zephyr/boards/nxp/rddrone_fmuk66/rddrone_fmuk66.dts:87 */
		standby-gpios = < &gpioc 0x12 0x0 >; /* in zephyr/boards/nxp/rddrone_fmuk66/rddrone_fmuk66.dts:88 */
		#phy-cells = < 0x0 >;                /* in zephyr/boards/nxp/rddrone_fmuk66/rddrone_fmuk66.dts:89 */
		phandle = < 0x22 >;                  /* in zephyr/boards/nxp/rddrone_fmuk66/rddrone_fmuk66.dts:300 */
	};

	/* node '/reg-3v3-s' defined in zephyr/boards/nxp/rddrone_fmuk66/rddrone_fmuk66.dts:93 */
	reg-3v3-s {
		compatible = "regulator-fixed";    /* in zephyr/boards/nxp/rddrone_fmuk66/rddrone_fmuk66.dts:94 */
		regulator-name = "reg-3v3-s";      /* in zephyr/boards/nxp/rddrone_fmuk66/rddrone_fmuk66.dts:95 */
		enable-gpios = < &gpiob 0x8 0x0 >; /* in zephyr/boards/nxp/rddrone_fmuk66/rddrone_fmuk66.dts:96 */
		startup-delay-us = < 0x7d0 >;      /* in zephyr/boards/nxp/rddrone_fmuk66/rddrone_fmuk66.dts:97 */
		regulator-always-on;               /* in zephyr/boards/nxp/rddrone_fmuk66/rddrone_fmuk66.dts:98 */
		status = "okay";                   /* in zephyr/boards/nxp/rddrone_fmuk66/rddrone_fmuk66.dts:99 */
	};

	/* node '/reg-3v3-neth' defined in zephyr/boards/nxp/rddrone_fmuk66/rddrone_fmuk66.dts:103 */
	reg-3v3-neth {
		compatible = "regulator-fixed";    /* in zephyr/boards/nxp/rddrone_fmuk66/rddrone_fmuk66.dts:104 */
		regulator-name = "reg-3v3-neth";   /* in zephyr/boards/nxp/rddrone_fmuk66/rddrone_fmuk66.dts:105 */
		enable-gpios = < &gpiob 0x3 0x1 >; /* in zephyr/boards/nxp/rddrone_fmuk66/rddrone_fmuk66.dts:106 */
		regulator-always-on;               /* in zephyr/boards/nxp/rddrone_fmuk66/rddrone_fmuk66.dts:107 */
		status = "okay";                   /* in zephyr/boards/nxp/rddrone_fmuk66/rddrone_fmuk66.dts:108 */
	};

	/* node '/reg-3v3-sd' defined in zephyr/boards/nxp/rddrone_fmuk66/rddrone_fmuk66.dts:112 */
	reg-3v3-sd {
		compatible = "regulator-fixed";    /* in zephyr/boards/nxp/rddrone_fmuk66/rddrone_fmuk66.dts:113 */
		regulator-name = "reg-3v3-sd";     /* in zephyr/boards/nxp/rddrone_fmuk66/rddrone_fmuk66.dts:114 */
		enable-gpios = < &gpiod 0x6 0x0 >; /* in zephyr/boards/nxp/rddrone_fmuk66/rddrone_fmuk66.dts:115 */
		regulator-always-on;               /* in zephyr/boards/nxp/rddrone_fmuk66/rddrone_fmuk66.dts:116 */
		status = "okay";                   /* in zephyr/boards/nxp/rddrone_fmuk66/rddrone_fmuk66.dts:117 */
	};
};
